AUTOSAR XML (schema 4-2-1)
package /MICROSAR/Dem_swc/DataTypes
  23 x impl type:
    Dem_EventIdType: range raw 1..65535, implementation-data-type=uint16
    Dem_RatioIdType: range raw 1..65535, implementation-data-type=uint16
    Dem_DTCStatusMaskType: range raw 0..255, implementation-data-type=uint8
    Dem_OperationCycleIdType: range raw 0..255, implementation-data-type=uint8
    Dem_DTCGroupType: range raw 0..16777215, implementation-data-type=uint32
    Dem_EventStatusType: compu {0=DEM_EVENT_STATUS_PASSED, 1=DEM_EVENT_STATUS_FAILED, 2=DEM_EVENT_STATUS_PREPASSED, 3=DEM_EVENT_STATUS_PREFAILED, 4=DEM_EVENT_STATUS_FDC_THRESHOLD_REACHED, 5=DEM_EVENT_STATUS_PASSED_CONDITIONS_NOT_FULFILLED, 6=DEM_EVENT_STATUS_FAILED_CONDITIONS_NOT_FULFILLED, 7=DEM_EVENT_STATUS_PREPASSED_CONDITIONS_NOT_FULFILLED, 8=DEM_EVENT_STATUS_PREFAILED_CONDITIONS_NOT_FULFILLED}, implementation-data-type=uint8
    Dem_InitMonitorReasonType: compu {1=DEM_INIT_MONITOR_CLEAR, 2=DEM_INIT_MONITOR_RESTART, 3=DEM_INIT_MONITOR_REENABLED, 4=DEM_INIT_MONITOR_STORAGE_REENABLED}, implementation-data-type=uint8
    Dem_DTCOriginType: compu {1=DEM_DTC_ORIGIN_PRIMARY_MEMORY, 2=DEM_DTC_ORIGIN_MIRROR_MEMORY, 3=DEM_DTC_ORIGIN_PERMANENT_MEMORY, 4=DEM_DTC_ORIGIN_OBD_RELEVANT_MEMORY, 5=DEM_DTC_ORIGIN_SECONDARY_MEMORY, 5=DEM_DTC_ORIGIN_USERDEFINED_MEMORY_10, 5=DEM_DTC_ORIGIN_USERDEFINED_MEMORY_11, 5=DEM_DTC_ORIGIN_USERDEFINED_MEMORY_12, 5=DEM_DTC_ORIGIN_USERDEFINED_MEMORY_13, 5=DEM_DTC_ORIGIN_USERDEFINED_MEMORY_14, 5=DEM_DTC_ORIGIN_USERDEFINED_MEMORY_15, 5=DEM_DTC_ORIGIN_USERDEFINED_MEMORY_16, 5=DEM_DTC_ORIGIN_USERDEFINED_MEMORY_17, 5=DEM_DTC_ORIGIN_USERDEFINED_MEMORY_18, 5=DEM_DTC_ORIGIN_USERDEFINED_MEMORY_19, 5=DEM_DTC_ORIGIN_USERDEFINED_MEMORY_1A, 5=DEM_DTC_ORIGIN_USERDEFINED_MEMORY_1B, 5=DEM_DTC_ORIGIN_USERDEFINED_MEMORY_1C, 5=DEM_DTC_ORIGIN_USERDEFINED_MEMORY_1D, 5=DEM_DTC_ORIGIN_USERDEFINED_MEMORY_1E, 5=DEM_DTC_ORIGIN_USERDEFINED_MEMORY_1F, 5=DEM_DTC_ORIGIN_USERDEFINED_MEMORY_20, 5=DEM_DTC_ORIGIN_USERDEFINED_MEMORY_21, 5=DEM_DTC_ORIGIN_USERDEFINED_MEMORY_22, 5=DEM_DTC_ORIGIN_USERDEFINED_MEMORY_23, 5=DEM_DTC_ORIGIN_USERDEFINED_MEMORY_24, 5=DEM_DTC_ORIGIN_USERDEFINED_MEMORY_25, 5=DEM_DTC_ORIGIN_USERDEFINED_MEMORY_26, 5=DEM_DTC_ORIGIN_USERDEFINED_MEMORY_27, 5=DEM_DTC_ORIGIN_USERDEFINED_MEMORY_28, 5=DEM_DTC_ORIGIN_USERDEFINED_MEMORY_29, 5=DEM_DTC_ORIGIN_USERDEFINED_MEMORY_2A, 5=DEM_DTC_ORIGIN_USERDEFINED_MEMORY_2B, 5=DEM_DTC_ORIGIN_USERDEFINED_MEMORY_2C, 5=DEM_DTC_ORIGIN_USERDEFINED_MEMORY_2D, 5=DEM_DTC_ORIGIN_USERDEFINED_MEMORY_2E, 5=DEM_DTC_ORIGIN_USERDEFINED_MEMORY_2F, 5=DEM_DTC_ORIGIN_USERDEFINED_MEMORY_30, 5=DEM_DTC_ORIGIN_USERDEFINED_MEMORY_31, 5=DEM_DTC_ORIGIN_USERDEFINED_MEMORY_32, 5=DEM_DTC_ORIGIN_USERDEFINED_MEMORY_33, 5=DEM_DTC_ORIGIN_USERDEFINED_MEMORY_34, 5=DEM_DTC_ORIGIN_USERDEFINED_MEMORY_35, 5=DEM_DTC_ORIGIN_USERDEFINED_MEMORY_36, 5=DEM_DTC_ORIGIN_USERDEFINED_MEMORY_37, 5=DEM_DTC_ORIGIN_USERDEFINED_MEMORY_38, 5=DEM_DTC_ORIGIN_USERDEFINED_MEMORY_39, 5=DEM_DTC_ORIGIN_USERDEFINED_MEMORY_3A, 5=DEM_DTC_ORIGIN_USERDEFINED_MEMORY_3B, 5=DEM_DTC_ORIGIN_USERDEFINED_MEMORY_3C, 5=DEM_DTC_ORIGIN_USERDEFINED_MEMORY_3D, 5=DEM_DTC_ORIGIN_USERDEFINED_MEMORY_3E, 5=DEM_DTC_ORIGIN_USERDEFINED_MEMORY_3F, 5=DEM_DTC_ORIGIN_USERDEFINED_MEMORY_40, 5=DEM_DTC_ORIGIN_USERDEFINED_MEMORY_41, 5=DEM_DTC_ORIGIN_USERDEFINED_MEMORY_42, 5=DEM_DTC_ORIGIN_USERDEFINED_MEMORY_43, 5=DEM_DTC_ORIGIN_USERDEFINED_MEMORY_44, 5=DEM_DTC_ORIGIN_USERDEFINED_MEMORY_45, 5=DEM_DTC_ORIGIN_USERDEFINED_MEMORY_46, 5=DEM_DTC_ORIGIN_USERDEFINED_MEMORY_47, 5=DEM_DTC_ORIGIN_USERDEFINED_MEMORY_48, 5=DEM_DTC_ORIGIN_USERDEFINED_MEMORY_49, 5=DEM_DTC_ORIGIN_USERDEFINED_MEMORY_4A, 5=DEM_DTC_ORIGIN_USERDEFINED_MEMORY_4B, 5=DEM_DTC_ORIGIN_USERDEFINED_MEMORY_4C, 5=DEM_DTC_ORIGIN_USERDEFINED_MEMORY_4D, 5=DEM_DTC_ORIGIN_USERDEFINED_MEMORY_4E, 5=DEM_DTC_ORIGIN_USERDEFINED_MEMORY_4F, 5=DEM_DTC_ORIGIN_USERDEFINED_MEMORY_50, 5=DEM_DTC_ORIGIN_USERDEFINED_MEMORY_51, 5=DEM_DTC_ORIGIN_USERDEFINED_MEMORY_52, 5=DEM_DTC_ORIGIN_USERDEFINED_MEMORY_53, 5=DEM_DTC_ORIGIN_USERDEFINED_MEMORY_54, 5=DEM_DTC_ORIGIN_USERDEFINED_MEMORY_55, 5=DEM_DTC_ORIGIN_USERDEFINED_MEMORY_56, 5=DEM_DTC_ORIGIN_USERDEFINED_MEMORY_57, 5=DEM_DTC_ORIGIN_USERDEFINED_MEMORY_58, 5=DEM_DTC_ORIGIN_USERDEFINED_MEMORY_59, 5=DEM_DTC_ORIGIN_USERDEFINED_MEMORY_5A, 5=DEM_DTC_ORIGIN_USERDEFINED_MEMORY_5B, 5=DEM_DTC_ORIGIN_USERDEFINED_MEMORY_5C, 5=DEM_DTC_ORIGIN_USERDEFINED_MEMORY_5D, 5=DEM_DTC_ORIGIN_USERDEFINED_MEMORY_5E, 5=DEM_DTC_ORIGIN_USERDEFINED_MEMORY_5F, 5=DEM_DTC_ORIGIN_USERDEFINED_MEMORY_60, 5=DEM_DTC_ORIGIN_USERDEFINED_MEMORY_61, 5=DEM_DTC_ORIGIN_USERDEFINED_MEMORY_62, 5=DEM_DTC_ORIGIN_USERDEFINED_MEMORY_63, 5=DEM_DTC_ORIGIN_USERDEFINED_MEMORY_64, 5=DEM_DTC_ORIGIN_USERDEFINED_MEMORY_65, 5=DEM_DTC_ORIGIN_USERDEFINED_MEMORY_66, 5=DEM_DTC_ORIGIN_USERDEFINED_MEMORY_67, 5=DEM_DTC_ORIGIN_USERDEFINED_MEMORY_68, 5=DEM_DTC_ORIGIN_USERDEFINED_MEMORY_69, 5=DEM_DTC_ORIGIN_USERDEFINED_MEMORY_6A, 5=DEM_DTC_ORIGIN_USERDEFINED_MEMORY_6B, 5=DEM_DTC_ORIGIN_USERDEFINED_MEMORY_6C, 5=DEM_DTC_ORIGIN_USERDEFINED_MEMORY_6D, 5=DEM_DTC_ORIGIN_USERDEFINED_MEMORY_6E, 5=DEM_DTC_ORIGIN_USERDEFINED_MEMORY_6F, 5=DEM_DTC_ORIGIN_USERDEFINED_MEMORY_70, 5=DEM_DTC_ORIGIN_USERDEFINED_MEMORY_71, 5=DEM_DTC_ORIGIN_USERDEFINED_MEMORY_72, 5=DEM_DTC_ORIGIN_USERDEFINED_MEMORY_73, 5=DEM_DTC_ORIGIN_USERDEFINED_MEMORY_74, 5=DEM_DTC_ORIGIN_USERDEFINED_MEMORY_75, 5=DEM_DTC_ORIGIN_USERDEFINED_MEMORY_76, 5=DEM_DTC_ORIGIN_USERDEFINED_MEMORY_77, 5=DEM_DTC_ORIGIN_USERDEFINED_MEMORY_78, 5=DEM_DTC_ORIGIN_USERDEFINED_MEMORY_79, 5=DEM_DTC_ORIGIN_USERDEFINED_MEMORY_7A, 5=DEM_DTC_ORIGIN_USERDEFINED_MEMORY_7B, 5=DEM_DTC_ORIGIN_USERDEFINED_MEMORY_7C, 5=DEM_DTC_ORIGIN_USERDEFINED_MEMORY_7D, 5=DEM_DTC_ORIGIN_USERDEFINED_MEMORY_7E, 5=DEM_DTC_ORIGIN_USERDEFINED_MEMORY_7F, 5=DEM_DTC_ORIGIN_USERDEFINED_MEMORY_80, 5=DEM_DTC_ORIGIN_USERDEFINED_MEMORY_81, 5=DEM_DTC_ORIGIN_USERDEFINED_MEMORY_82, 5=DEM_DTC_ORIGIN_USERDEFINED_MEMORY_83, 5=DEM_DTC_ORIGIN_USERDEFINED_MEMORY_84, 5=DEM_DTC_ORIGIN_USERDEFINED_MEMORY_85, 5=DEM_DTC_ORIGIN_USERDEFINED_MEMORY_86, 5=DEM_DTC_ORIGIN_USERDEFINED_MEMORY_87, 5=DEM_DTC_ORIGIN_USERDEFINED_MEMORY_88, 5=DEM_DTC_ORIGIN_USERDEFINED_MEMORY_89, 5=DEM_DTC_ORIGIN_USERDEFINED_MEMORY_8A, 5=DEM_DTC_ORIGIN_USERDEFINED_MEMORY_8B, 5=DEM_DTC_ORIGIN_USERDEFINED_MEMORY_8C, 5=DEM_DTC_ORIGIN_USERDEFINED_MEMORY_8D, 5=DEM_DTC_ORIGIN_USERDEFINED_MEMORY_8E, 5=DEM_DTC_ORIGIN_USERDEFINED_MEMORY_8F, 5=DEM_DTC_ORIGIN_USERDEFINED_MEMORY_90, 5=DEM_DTC_ORIGIN_USERDEFINED_MEMORY_91, 5=DEM_DTC_ORIGIN_USERDEFINED_MEMORY_92, 5=DEM_DTC_ORIGIN_USERDEFINED_MEMORY_93, 5=DEM_DTC_ORIGIN_USERDEFINED_MEMORY_94, 5=DEM_DTC_ORIGIN_USERDEFINED_MEMORY_95, 5=DEM_DTC_ORIGIN_USERDEFINED_MEMORY_96, 5=DEM_DTC_ORIGIN_USERDEFINED_MEMORY_97, 5=DEM_DTC_ORIGIN_USERDEFINED_MEMORY_98, 5=DEM_DTC_ORIGIN_USERDEFINED_MEMORY_99, 5=DEM_DTC_ORIGIN_USERDEFINED_MEMORY_9A, 5=DEM_DTC_ORIGIN_USERDEFINED_MEMORY_9B, 5=DEM_DTC_ORIGIN_USERDEFINED_MEMORY_9C, 5=DEM_DTC_ORIGIN_USERDEFINED_MEMORY_9D, 5=DEM_DTC_ORIGIN_USERDEFINED_MEMORY_9E, 5=DEM_DTC_ORIGIN_USERDEFINED_MEMORY_9F, 5=DEM_DTC_ORIGIN_USERDEFINED_MEMORY_A0, 5=DEM_DTC_ORIGIN_USERDEFINED_MEMORY_A1, 5=DEM_DTC_ORIGIN_USERDEFINED_MEMORY_A2, 5=DEM_DTC_ORIGIN_USERDEFINED_MEMORY_A3, 5=DEM_DTC_ORIGIN_USERDEFINED_MEMORY_A4, 5=DEM_DTC_ORIGIN_USERDEFINED_MEMORY_A5, 5=DEM_DTC_ORIGIN_USERDEFINED_MEMORY_A6, 5=DEM_DTC_ORIGIN_USERDEFINED_MEMORY_A7, 5=DEM_DTC_ORIGIN_USERDEFINED_MEMORY_A8, 5=DEM_DTC_ORIGIN_USERDEFINED_MEMORY_A9, 5=DEM_DTC_ORIGIN_USERDEFINED_MEMORY_AA, 5=DEM_DTC_ORIGIN_USERDEFINED_MEMORY_AB, 5=DEM_DTC_ORIGIN_USERDEFINED_MEMORY_AC, 5=DEM_DTC_ORIGIN_USERDEFINED_MEMORY_AD, 5=DEM_DTC_ORIGIN_USERDEFINED_MEMORY_AE, 5=DEM_DTC_ORIGIN_USERDEFINED_MEMORY_AF, 5=DEM_DTC_ORIGIN_USERDEFINED_MEMORY_B0, 5=DEM_DTC_ORIGIN_USERDEFINED_MEMORY_B1, 5=DEM_DTC_ORIGIN_USERDEFINED_MEMORY_B2, 5=DEM_DTC_ORIGIN_USERDEFINED_MEMORY_B3, 5=DEM_DTC_ORIGIN_USERDEFINED_MEMORY_B4, 5=DEM_DTC_ORIGIN_USERDEFINED_MEMORY_B5, 5=DEM_DTC_ORIGIN_USERDEFINED_MEMORY_B6, 5=DEM_DTC_ORIGIN_USERDEFINED_MEMORY_B7, 5=DEM_DTC_ORIGIN_USERDEFINED_MEMORY_B8, 5=DEM_DTC_ORIGIN_USERDEFINED_MEMORY_B9, 5=DEM_DTC_ORIGIN_USERDEFINED_MEMORY_BA, 5=DEM_DTC_ORIGIN_USERDEFINED_MEMORY_BB, 5=DEM_DTC_ORIGIN_USERDEFINED_MEMORY_BC, 5=DEM_DTC_ORIGIN_USERDEFINED_MEMORY_BD, 5=DEM_DTC_ORIGIN_USERDEFINED_MEMORY_BE, 5=DEM_DTC_ORIGIN_USERDEFINED_MEMORY_BF, 5=DEM_DTC_ORIGIN_USERDEFINED_MEMORY_C0, 5=DEM_DTC_ORIGIN_USERDEFINED_MEMORY_C1, 5=DEM_DTC_ORIGIN_USERDEFINED_MEMORY_C2, 5=DEM_DTC_ORIGIN_USERDEFINED_MEMORY_C3, 5=DEM_DTC_ORIGIN_USERDEFINED_MEMORY_C4, 5=DEM_DTC_ORIGIN_USERDEFINED_MEMORY_C5, 5=DEM_DTC_ORIGIN_USERDEFINED_MEMORY_C6, 5=DEM_DTC_ORIGIN_USERDEFINED_MEMORY_C7, 5=DEM_DTC_ORIGIN_USERDEFINED_MEMORY_C8, 5=DEM_DTC_ORIGIN_USERDEFINED_MEMORY_C9, 5=DEM_DTC_ORIGIN_USERDEFINED_MEMORY_CA, 5=DEM_DTC_ORIGIN_USERDEFINED_MEMORY_CB, 5=DEM_DTC_ORIGIN_USERDEFINED_MEMORY_CC, 5=DEM_DTC_ORIGIN_USERDEFINED_MEMORY_CD, 5=DEM_DTC_ORIGIN_USERDEFINED_MEMORY_CE, 5=DEM_DTC_ORIGIN_USERDEFINED_MEMORY_CF, 5=DEM_DTC_ORIGIN_USERDEFINED_MEMORY_D0, 5=DEM_DTC_ORIGIN_USERDEFINED_MEMORY_D1, 5=DEM_DTC_ORIGIN_USERDEFINED_MEMORY_D2, 5=DEM_DTC_ORIGIN_USERDEFINED_MEMORY_D3, 5=DEM_DTC_ORIGIN_USERDEFINED_MEMORY_D4, 5=DEM_DTC_ORIGIN_USERDEFINED_MEMORY_D5, 5=DEM_DTC_ORIGIN_USERDEFINED_MEMORY_D6, 5=DEM_DTC_ORIGIN_USERDEFINED_MEMORY_D7, 5=DEM_DTC_ORIGIN_USERDEFINED_MEMORY_D8, 5=DEM_DTC_ORIGIN_USERDEFINED_MEMORY_D9, 5=DEM_DTC_ORIGIN_USERDEFINED_MEMORY_DA, 5=DEM_DTC_ORIGIN_USERDEFINED_MEMORY_DB, 5=DEM_DTC_ORIGIN_USERDEFINED_MEMORY_DC, 5=DEM_DTC_ORIGIN_USERDEFINED_MEMORY_DD, 5=DEM_DTC_ORIGIN_USERDEFINED_MEMORY_DE, 5=DEM_DTC_ORIGIN_USERDEFINED_MEMORY_DF, 5=DEM_DTC_ORIGIN_USERDEFINED_MEMORY_E0, 5=DEM_DTC_ORIGIN_USERDEFINED_MEMORY_E1, 5=DEM_DTC_ORIGIN_USERDEFINED_MEMORY_E2, 5=DEM_DTC_ORIGIN_USERDEFINED_MEMORY_E3, 5=DEM_DTC_ORIGIN_USERDEFINED_MEMORY_E4, 5=DEM_DTC_ORIGIN_USERDEFINED_MEMORY_E5, 5=DEM_DTC_ORIGIN_USERDEFINED_MEMORY_E6, 5=DEM_DTC_ORIGIN_USERDEFINED_MEMORY_E7, 5=DEM_DTC_ORIGIN_USERDEFINED_MEMORY_E8, 5=DEM_DTC_ORIGIN_USERDEFINED_MEMORY_E9, 5=DEM_DTC_ORIGIN_USERDEFINED_MEMORY_EA, 5=DEM_DTC_ORIGIN_USERDEFINED_MEMORY_EB, 5=DEM_DTC_ORIGIN_USERDEFINED_MEMORY_EC, 5=DEM_DTC_ORIGIN_USERDEFINED_MEMORY_ED, 5=DEM_DTC_ORIGIN_USERDEFINED_MEMORY_EE, 5=DEM_DTC_ORIGIN_USERDEFINED_MEMORY_EF, 5=DEM_DTC_ORIGIN_USERDEFINED_MEMORY_F0, 5=DEM_DTC_ORIGIN_USERDEFINED_MEMORY_F1, 5=DEM_DTC_ORIGIN_USERDEFINED_MEMORY_F2, 5=DEM_DTC_ORIGIN_USERDEFINED_MEMORY_F3, 5=DEM_DTC_ORIGIN_USERDEFINED_MEMORY_F4, 5=DEM_DTC_ORIGIN_USERDEFINED_MEMORY_F5, 5=DEM_DTC_ORIGIN_USERDEFINED_MEMORY_F6, 5=DEM_DTC_ORIGIN_USERDEFINED_MEMORY_F7, 5=DEM_DTC_ORIGIN_USERDEFINED_MEMORY_F8, 5=DEM_DTC_ORIGIN_USERDEFINED_MEMORY_F9, 5=DEM_DTC_ORIGIN_USERDEFINED_MEMORY_FA, 5=DEM_DTC_ORIGIN_USERDEFINED_MEMORY_FB, 5=DEM_DTC_ORIGIN_USERDEFINED_MEMORY_FC, 5=DEM_DTC_ORIGIN_USERDEFINED_MEMORY_FD, 5=DEM_DTC_ORIGIN_USERDEFINED_MEMORY_FE, 5=DEM_DTC_ORIGIN_USERDEFINED_MEMORY_FF}, implementation-data-type=uint16
    Dem_DTCFormatType: compu {0=DEM_DTC_FORMAT_OBD, 1=DEM_DTC_FORMAT_UDS, 2=DEM_DTC_FORMAT_J1939}, implementation-data-type=uint8
    Dem_OperationCycleStateType: compu {0=DEM_CYCLE_STATE_START, 1=DEM_CYCLE_STATE_END}, implementation-data-type=uint8
    Dem_IndicatorStatusType: compu {0=DEM_INDICATOR_OFF, 1=DEM_INDICATOR_CONTINUOUS, 2=DEM_INDICATOR_BLINKING, 3=DEM_INDICATOR_BLINK_CONT, 4=DEM_INDICATOR_SLOW_FLASH, 5=DEM_INDICATOR_FAST_FLASH, 6=DEM_INDICATOR_ON_DEMAND, 7=DEM_INDICATOR_SHORT}, implementation-data-type=uint8
    Dem_DTCKindType: compu {1=DEM_DTC_KIND_ALL_DTCS, 2=DEM_DTC_KIND_EMISSION_REL_DTCS}, implementation-data-type=uint8
    Dem_IumprDenomCondIdType: compu {1=DEM_IUMPR_GENERAL_DENOMINATOR, 2=DEM_IUMPR_DEN_COND_COLDSTART, 3=DEM_IUMPR_DEN_COND_EVAP, 4=DEM_IUMPR_DEN_COND_500MI}, implementation-data-type=uint8
    Dem_IumprDenomCondStatusType: compu {0=DEM_IUMPR_DEN_STATUS_NOT_REACHED, 1=DEM_IUMPR_DEN_STATUS_REACHED, 2=DEM_IUMPR_DEN_STATUS_INHIBITED}, implementation-data-type=uint8
    Dem_DebounceResetStatusType: compu {0=DEM_DEBOUNCE_STATUS_FREEZE, 1=DEM_DEBOUNCE_STATUS_RESET}, implementation-data-type=uint8
    Dem_IumprReadinessGroupType: compu {0=DEM_IUMPR_BOOSTPRS, 1=DEM_IUMPR_CAT1, 2=DEM_IUMPR_CAT2, 3=DEM_IUMPR_EGR, 4=DEM_IUMPR_EGSENSOR, 5=DEM_IUMPR_EVAP, 6=DEM_IUMPR_NMHCCAT, 7=DEM_IUMPR_NOXADSORB, 8=DEM_IUMPR_NOXCAT, 9=DEM_IUMPR_OXS1, 10=DEM_IUMPR_OXS2, 11=DEM_IUMPR_PMFILTER, 12=DEM_IUMPR_PRIVATE, 13=DEM_IUMPR_SAIR, 14=DEM_IUMPR_SECOXS1, 15=DEM_IUMPR_SECOXS2, 16=DEM_IUMPR_FLSYS, 255=DEM_IUMPR_ALLGROUPS}, implementation-data-type=uint8
    Dem_DTRControlType: compu {0=DEM_DTR_CTL_NORMAL, 1=DEM_DTR_CTL_NO_MAX, 2=DEM_DTR_CTL_NO_MIN, 3=DEM_DTR_CTL_RESET, 4=DEM_DTR_CTL_INVISIBLE}, implementation-data-type=uint8
    Dem_DebouncingStateType: compu {mask 1: 1=DEM_TEMPORARILY_DEFECTIVE, mask 2: 2=DEM_FINALLY_DEFECTIVE, mask 4: 4=DEM_TEMPORARILY_HEALED, mask 8: 8=DEM_TEST_COMPLETE, mask 16: 16=DEM_DTR_UPDATE}, range raw 0..255, implementation-data-type=uint8
    Dem_DTCSeverityType:
      compu {mask 255: 0=DEM_SEVERITY_NO_SEVERITY, mask 31: 2=DEM_SEVERITY_WWHOBD_CLASS_A, mask 31: 4=DEM_SEVERITY_WWHOBD_CLASS_B1, mask 31: 8=DEM_SEVERITY_WWHOBD_CLASS_B2, mask 31: 16=DEM_SEVERITY_WWHOBD_CLASS_C, mask 31: 1=DEM_SEVERITY_WWHOBD_CLASS_NO_CLASS, mask 224: 64=DEM_SEVERITY_CHECK_AT_NEXT_HALT, mask 224: 128=DEM_SEVERITY_CHECK_IMMEDIATELY, mask 224: 32=DEM_SEVERITY_MAINTENANCE_ONLY}
      range raw 0..255
      implementation-data-type=uint8
    Dem_UdsStatusByteType: compu {mask 1: 1=DEM_UDS_STATUS_TF, mask 2: 2=DEM_UDS_STATUS_TFTOC, mask 4: 4=DEM_UDS_STATUS_PDTC, mask 8: 8=DEM_UDS_STATUS_CDTC, mask 16: 16=DEM_UDS_STATUS_TNCSLC, mask 32: 32=DEM_UDS_STATUS_TFSLC, mask 64: 64=DEM_UDS_STATUS_TNCTOC, mask 128: 128=DEM_UDS_STATUS_WIR}, range raw 0..255, implementation-data-type=uint8
    Dem_MonitorStatusType: compu {mask 1: 1=DEM_MONITOR_STATUS_TF, mask 2: 2=DEM_MONITOR_STATUS_TNCTOC}, range raw 0..255, implementation-data-type=uint8
    Dem_MaxDataValueType: category=ARRAY, sw-calibration-access=READ-ONLY
      element Dem_MaxDataValueTypeElement: array-size=4, array-size-semantics=FIXED-SIZE, implementation-data-type=uint8
    DataArrayType_uint8_4: category=ARRAY, sw-calibration-access=READ-ONLY
      element DataArrayType_uint8_4Element: array-size=4, array-size-semantics=FIXED-SIZE, implementation-data-type=uint8
package /MICROSAR/Dem_swc/Interfaces
  9 x client server interface, all with is-service=true, service-kind=DIAGNOSTIC-EVENT-MANAGER:
    DemServices
      operation GetPostRunRequested: possible-error=DemServices/E_NOT_OK
        arg IsRequested: type=boolean, direction=OUT
      operation GetDTCStatusAvailabilityMask: possible-error=DemServices/E_NOT_OK
        arg ClientId: type=uint8, direction=IN
        arg DTCStatusMask: type=uint8, direction=OUT
      error E_NOT_OK: error-code=1
    ClearDTC
      operation ClearDTC: possible-error=[ClearDTC/E_NOT_OK, DEM_CLEAR_FAILED, DEM_PENDING, DEM_CLEAR_BUSY, DEM_CLEAR_MEMORY_ERROR, DEM_WRONG_DTC, DEM_WRONG_DTCORIGIN]
      operation SelectDTC: possible-error=[ClearDTC/E_OK, ClearDTC/E_NOT_OK]
        arg DTC: type=uint32, direction=IN
        arg DTCFormat: type=Dem_DTCFormatType, direction=IN
        arg DTCOrigin: type=Dem_DTCOriginType, direction=IN
      8 x error:
        E_OK: error-code=0
        E_NOT_OK: error-code=1
        DEM_CLEAR_FAILED: error-code=7
        DEM_PENDING: error-code=4
        DEM_CLEAR_BUSY: error-code=5
        DEM_CLEAR_MEMORY_ERROR: error-code=6
        DEM_WRONG_DTC: error-code=8
        DEM_WRONG_DTCORIGIN: error-code=9
    EvMemOverflowIndication
      operation GetEventMemoryOverflow: possible-error=EvMemOverflowIndication/E_NOT_OK
        arg OverflowIndication: type=boolean, direction=OUT
      operation GetNumberOfEventMemoryEntries: possible-error=EvMemOverflowIndication/E_NOT_OK
        arg NumberOfEventMemoryEntries: type=uint8, direction=OUT
      error E_NOT_OK: error-code=1
    OperationCycle
      operation GetOperationCycleState: possible-error=[OperationCycle/E_OK, OperationCycle/E_NOT_OK]
        arg CycleState: type=Dem_OperationCycleStateType, direction=OUT
      operation SetOperationCycleState: possible-error=[OperationCycle/E_OK, OperationCycle/E_NOT_OK]
        arg CycleState: type=Dem_OperationCycleStateType, direction=IN
      error E_OK: error-code=0
      error E_NOT_OK: error-code=1
    GeneralDiagnosticInfo
      11 x operation:
        GetEventUdsStatus: possible-error=GeneralDiagnosticInfo/E_NOT_OK
          arg EventId: type=Dem_EventIdType, direction=IN
          arg UDSStatusByte: type=Dem_UdsStatusByteType, direction=OUT
        GetEventStatus: possible-error=GeneralDiagnosticInfo/E_NOT_OK
          arg EventId: type=Dem_EventIdType, direction=IN
          arg UDSStatusByte: type=Dem_UdsStatusByteType, direction=OUT
        GetEventFailed: possible-error=GeneralDiagnosticInfo/E_NOT_OK
          arg EventId: type=Dem_EventIdType, direction=IN
          arg EventFailed: type=boolean, direction=OUT
        GetEventTested: possible-error=GeneralDiagnosticInfo/E_NOT_OK
          arg EventId: type=Dem_EventIdType, direction=IN
          arg EventTested: type=boolean, direction=OUT
        GetDTCOfEvent: possible-error=[GeneralDiagnosticInfo/E_NOT_OK, GeneralDiagnosticInfo/DEM_E_NO_DTC_AVAILABLE]
          arg EventId: type=Dem_EventIdType, direction=IN
          arg DTCFormat: type=Dem_DTCFormatType, direction=IN
          arg DTCOfEvent: type=uint32, direction=OUT
        GetFaultDetectionCounter: possible-error=[GeneralDiagnosticInfo/E_NOT_OK, GeneralDiagnosticInfo/DEM_E_NO_FDC_AVAILABLE]
          arg EventId: type=Dem_EventIdType, direction=IN
          arg FaultDetectionCounter: type=sint8, direction=OUT
        GetEventFreezeFrameDataEx: possible-error=[GeneralDiagnosticInfo/E_NOT_OK, GeneralDiagnosticInfo/DEM_BUFFER_TOO_SMALL, GeneralDiagnosticInfo/DEM_NO_SUCH_ELEMENT]
          5 x arg:
            EventId: type=Dem_EventIdType, direction=IN
            RecordNumber: type=uint8, direction=IN
            DataId: type=uint16, direction=IN
            DestBuffer: type=Dem_MaxDataValueType, direction=OUT
            BufSize: type=uint16, direction=INOUT
        GetEventExtendedDataRecordEx: possible-error=[GeneralDiagnosticInfo/E_NOT_OK, GeneralDiagnosticInfo/DEM_BUFFER_TOO_SMALL, GeneralDiagnosticInfo/DEM_NO_SUCH_ELEMENT]
          4 x arg:
            EventId: type=Dem_EventIdType, direction=IN
            RecordNumber: type=uint8, direction=IN
            DestBuffer: type=Dem_MaxDataValueType, direction=OUT
            BufSize: type=uint16, direction=INOUT
        GetEventEnableCondition: possible-error=GeneralDiagnosticInfo/E_NOT_OK
          arg EventId: type=Dem_EventIdType, direction=IN
          arg ConditionFullfilled: type=boolean, direction=OUT
        GetDebouncingOfEvent: possible-error=GeneralDiagnosticInfo/E_NOT_OK
          arg EventId: type=Dem_EventIdType, direction=IN
          arg DebouncingState: type=Dem_DebouncingStateType, direction=OUT
        GetMonitorStatus: possible-error=GeneralDiagnosticInfo/E_NOT_OK
          arg EventId: type=Dem_EventIdType, direction=IN
          arg MonitorStatus: type=Dem_MonitorStatusType, direction=OUT
      5 x error:
        E_NOT_OK: error-code=1
        DEM_E_NO_DTC_AVAILABLE: error-code=10
        DEM_E_NO_FDC_AVAILABLE: error-code=14
        DEM_BUFFER_TOO_SMALL: error-code=21
        DEM_NO_SUCH_ELEMENT: error-code=48
    DiagnosticInfo
      11 x operation:
        GetEventUdsStatus: possible-error=DiagnosticInfo/E_NOT_OK
          arg UDSStatusByte: type=Dem_UdsStatusByteType, direction=OUT
        GetEventStatus: possible-error=DiagnosticInfo/E_NOT_OK
          arg UDSStatusByte: type=Dem_UdsStatusByteType, direction=OUT
        GetEventFailed: possible-error=DiagnosticInfo/E_NOT_OK
          arg EventFailed: type=boolean, direction=OUT
        GetEventTested: possible-error=DiagnosticInfo/E_NOT_OK
          arg EventTested: type=boolean, direction=OUT
        GetDTCOfEvent: possible-error=[DiagnosticInfo/E_NOT_OK, DiagnosticInfo/DEM_E_NO_DTC_AVAILABLE]
          arg DTCFormat: type=Dem_DTCFormatType, direction=IN
          arg DTCOfEvent: type=uint32, direction=OUT
        GetFaultDetectionCounter: possible-error=[DiagnosticInfo/E_NOT_OK, DiagnosticInfo/DEM_E_NO_FDC_AVAILABLE]
          arg FaultDetectionCounter: type=sint8, direction=OUT
        GetEventFreezeFrameDataEx: possible-error=[DiagnosticInfo/E_NOT_OK, DiagnosticInfo/DEM_BUFFER_TOO_SMALL, DiagnosticInfo/DEM_NO_SUCH_ELEMENT]
          4 x arg:
            RecordNumber: type=uint8, direction=IN
            DataId: type=uint16, direction=IN
            DestBuffer: type=Dem_MaxDataValueType, direction=OUT
            BufSize: type=uint16, direction=INOUT
        GetEventExtendedDataRecordEx: possible-error=[DiagnosticInfo/E_NOT_OK, DiagnosticInfo/DEM_BUFFER_TOO_SMALL, DiagnosticInfo/DEM_NO_SUCH_ELEMENT]
          arg RecordNumber: type=uint8, direction=IN
          arg DestBuffer: type=Dem_MaxDataValueType, direction=OUT
          arg BufSize: type=uint16, direction=INOUT
        GetEventEnableCondition: possible-error=DiagnosticInfo/E_NOT_OK
          arg ConditionFullfilled: type=boolean, direction=OUT
        GetDebouncingOfEvent: possible-error=DiagnosticInfo/E_NOT_OK
          arg DebouncingState: type=Dem_DebouncingStateType, direction=OUT
        GetMonitorStatus: possible-error=DiagnosticInfo/E_NOT_OK
          arg MonitorStatus: type=Dem_MonitorStatusType, direction=OUT
      5 x error:
        E_NOT_OK: error-code=1
        DEM_E_NO_DTC_AVAILABLE: error-code=10
        DEM_E_NO_FDC_AVAILABLE: error-code=14
        DEM_BUFFER_TOO_SMALL: error-code=21
        DEM_NO_SUCH_ELEMENT: error-code=48
    CSDataServices_OccurrenceCounter_OccurenceCounter
      operation ReadData: possible-error=CSDataServices_OccurrenceCounter_OccurenceCounter/E_NOT_OK
        arg Data: type=DataArrayType_uint8_4, direction=OUT
      error E_NOT_OK: error-code=1
    CSDataServices_OdometerValue_OdometerValue
      operation ReadData: possible-error=CSDataServices_OdometerValue_OdometerValue/E_NOT_OK
        arg Data: type=DataArrayType_uint8_4, direction=OUT
      error E_NOT_OK: error-code=1
    DiagnosticMonitor
      11 x operation:
        SetEventStatus: possible-error=DiagnosticMonitor/E_NOT_OK
          arg EventStatus: type=Dem_EventStatusType, direction=IN
        ResetEventStatus: possible-error=DiagnosticMonitor/E_NOT_OK
        ResetEventDebounceStatus: possible-error=DiagnosticMonitor/E_NOT_OK
          arg DebounceResetStatus: type=Dem_DebounceResetStatusType, direction=IN
        GetEventUdsStatus: possible-error=DiagnosticMonitor/E_NOT_OK
          arg UDSStatusByte: type=Dem_UdsStatusByteType, direction=OUT
        GetEventStatus: possible-error=DiagnosticMonitor/E_NOT_OK
          arg UDSStatusByte: type=Dem_UdsStatusByteType, direction=OUT
        GetEventFailed: possible-error=DiagnosticMonitor/E_NOT_OK
          arg EventFailed: type=boolean, direction=OUT
        GetEventTested: possible-error=DiagnosticMonitor/E_NOT_OK
          arg EventTested: type=boolean, direction=OUT
        GetDTCOfEvent: possible-error=[DiagnosticMonitor/E_NOT_OK, DiagnosticMonitor/DEM_E_NO_DTC_AVAILABLE]
          arg DTCFormat: type=Dem_DTCFormatType, direction=IN
          arg DTCOfEvent: type=uint32, direction=OUT
        GetFaultDetectionCounter: possible-error=[DiagnosticMonitor/E_NOT_OK, DiagnosticMonitor/DEM_E_NO_FDC_AVAILABLE]
          arg FaultDetectionCounter: type=sint8, direction=OUT
        GetEventFreezeFrameDataEx: possible-error=[DiagnosticMonitor/E_NOT_OK, DiagnosticMonitor/DEM_BUFFER_TOO_SMALL, DiagnosticMonitor/DEM_NO_SUCH_ELEMENT]
          4 x arg:
            RecordNumber: type=uint8, direction=IN
            DataId: type=uint16, direction=IN
            DestBuffer: type=Dem_MaxDataValueType, direction=OUT
            BufSize: type=uint16, direction=INOUT
        GetEventExtendedDataRecordEx: possible-error=[DiagnosticMonitor/E_NOT_OK, DiagnosticMonitor/DEM_BUFFER_TOO_SMALL, DiagnosticMonitor/DEM_NO_SUCH_ELEMENT]
          arg RecordNumber: type=uint8, direction=IN
          arg DestBuffer: type=Dem_MaxDataValueType, direction=OUT
          arg BufSize: type=uint16, direction=INOUT
      5 x error:
        E_NOT_OK: error-code=1
        DEM_E_NO_DTC_AVAILABLE: error-code=10
        DEM_E_NO_FDC_AVAILABLE: error-code=14
        DEM_BUFFER_TOO_SMALL: error-code=21
        DEM_NO_SUCH_ELEMENT: error-code=48
package /MICROSAR/Dem_swc/ComponentTypes
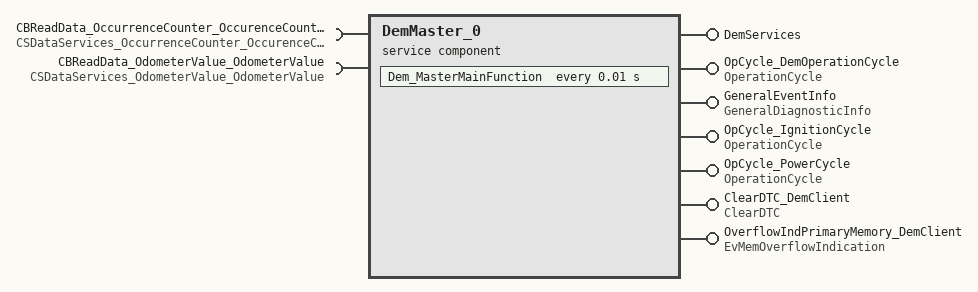
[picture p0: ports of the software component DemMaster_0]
  service sw component type DemMaster_0: category=SERVICE_COMPONENT
    5 x provide port:
      DemServices: provided-interface=DemServices
      OpCycle_DemOperationCycle: provided-interface=OperationCycle
      GeneralEventInfo: provided-interface=GeneralDiagnosticInfo
      OpCycle_IgnitionCycle: provided-interface=OperationCycle
      OpCycle_PowerCycle: provided-interface=OperationCycle
    require port CBReadData_OccurrenceCounter_OccurenceCounter: required-interface=CSDataServices_OccurrenceCounter_OccurenceCounter
    require port CBReadData_OdometerValue_OdometerValue: required-interface=CSDataServices_OdometerValue_OdometerValue
    provide port ClearDTC_DemClient: provided-interface=ClearDTC
    provide port OverflowIndPrimaryMemory_DemClient: provided-interface=EvMemOverflowIndication
    behavior DemMaster_0InternalBehavior: handle-termination-and-restart=NO-SUPPORT, included-data-type-set=data-type=[Dem_EventIdType, Dem_RatioIdType, Dem_EventStatusType, Dem_UdsStatusByteType, Dem_DTCFormatType, Dem_InitMonitorReasonType, Dem_OperationCycleStateType, Dem_DTCStatusMaskType, Dem_IndicatorStatusType, Dem_MaxDataValueType, Dem_DTCKindType, Dem_DTCGroupType, Dem_IumprDenomCondIdType, Dem_IumprDenomCondStatusType, Dem_DebounceResetStatusType, Dem_DebouncingStateType, Dem_IumprReadinessGroupType, Dem_DTRControlType, Dem_DTCSeverityType, Dem_MonitorStatusType]
      timing event Timer_Dem_MasterMainFunction: start-on-event=Dem_MasterMainFunction, period=0.01
      23 x operation invoked event:
        OpEventPostRunRequested_GetPostRunRequested_DemServices: start-on-event=PostRunRequested, operation=DemServices.GetPostRunRequested
        OpEventGetDTCStatusAvailabilityMask_GetDTCStatusAvailabilityMask_DemServices: start-on-event=GetDTCStatusAvailabilityMask, operation=DemServices.GetDTCStatusAvailabilityMask
        OpEventGetOperationCycleState_GetOperationCycleState_OpCycle_DemOperationCycle: start-on-event=GetOperationCycleState, operation=OpCycle_DemOperationCycle.GetOperationCycleState
        OpEventSetOperationCycleState_SetOperationCycleState_OpCycle_DemOperationCycle: start-on-event=SetOperationCycleState, operation=OpCycle_DemOperationCycle.SetOperationCycleState
        OpEventGetEventUdsStatus_GetEventUdsStatus_GeneralEventInfo: start-on-event=DemMaster_0InternalBehavior/GetEventUdsStatus, operation=GeneralEventInfo.GetEventUdsStatus
        OpEventGetEventStatus_GetEventStatus_GeneralEventInfo: start-on-event=DemMaster_0InternalBehavior/GetEventStatus, operation=GeneralEventInfo.GetEventStatus
        OpEventGetEventFailed_GetEventFailed_GeneralEventInfo: start-on-event=DemMaster_0InternalBehavior/GetEventFailed, operation=GeneralEventInfo.GetEventFailed
        OpEventGetEventTested_GetEventTested_GeneralEventInfo: start-on-event=DemMaster_0InternalBehavior/GetEventTested, operation=GeneralEventInfo.GetEventTested
        OpEventGetDTCOfEvent_GetDTCOfEvent_GeneralEventInfo: start-on-event=DemMaster_0InternalBehavior/GetDTCOfEvent, operation=GeneralEventInfo.GetDTCOfEvent
        OpEventGetFaultDetectionCounter_GetFaultDetectionCounter_GeneralEventInfo: start-on-event=DemMaster_0InternalBehavior/GetFaultDetectionCounter, operation=GeneralEventInfo.GetFaultDetectionCounter
        OpEventGetEventFreezeFrameDataEx_GetEventFreezeFrameDataEx_GeneralEventInfo: start-on-event=DemMaster_0InternalBehavior/GetEventFreezeFrameDataEx, operation=GeneralEventInfo.GetEventFreezeFrameDataEx
        OpEventGetEventExtendedDataRecordEx_GetEventExtendedDataRecordEx_GeneralEventInfo: start-on-event=DemMaster_0InternalBehavior/GetEventExtendedDataRecordEx, operation=GeneralEventInfo.GetEventExtendedDataRecordEx
        OpEventGetEventEnableCondition_GetEventEnableCondition_GeneralEventInfo: start-on-event=DemMaster_0InternalBehavior/GetEventEnableCondition, operation=GeneralEventInfo.GetEventEnableCondition
        OpEventGetDebouncingOfEvent_GetDebouncingOfEvent_GeneralEventInfo: start-on-event=DemMaster_0InternalBehavior/GetDebouncingOfEvent, operation=GeneralEventInfo.GetDebouncingOfEvent
        OpEventGetMonitorStatus_GetMonitorStatus_GeneralEventInfo: start-on-event=DemMaster_0InternalBehavior/GetMonitorStatus, operation=GeneralEventInfo.GetMonitorStatus
        OpEventGetOperationCycleState_GetOperationCycleState_OpCycle_IgnitionCycle: start-on-event=GetOperationCycleState, operation=OpCycle_IgnitionCycle.GetOperationCycleState
        OpEventGetOperationCycleState_GetOperationCycleState_OpCycle_PowerCycle: start-on-event=GetOperationCycleState, operation=OpCycle_PowerCycle.GetOperationCycleState
        OpEventSetOperationCycleState_SetOperationCycleState_OpCycle_IgnitionCycle: start-on-event=SetOperationCycleState, operation=OpCycle_IgnitionCycle.SetOperationCycleState
        OpEventSetOperationCycleState_SetOperationCycleState_OpCycle_PowerCycle: start-on-event=SetOperationCycleState, operation=OpCycle_PowerCycle.SetOperationCycleState
        OpEventClearDTC_ClearDTC_ClearDTC_DemClient: start-on-event=ClearDTC, operation=ClearDTC_DemClient.ClearDTC
        OpEventSelectDTC_SelectDTC_ClearDTC_DemClient: start-on-event=SelectDTC, operation=ClearDTC_DemClient.SelectDTC
        OpEventGetEventMemoryOverflow_GetEventMemoryOverflow_OverflowIndPrimaryMemory_DemClient: start-on-event=GetEventMemoryOverflow, operation=OverflowIndPrimaryMemory_DemClient.GetEventMemoryOverflow
        OpEventGetNumberOfEventMemoryEntries_GetNumberOfEventMemoryEntries_OverflowIndPrimaryMemory_DemClient: start-on-event=GetNumberOfEventMemoryEntries, operation=OverflowIndPrimaryMemory_DemClient.GetNumberOfEventMemoryEntries
      port-api-options:
        enable-take-address=true, indirect-api=false, port=DemServices
        {enable-take-address=true, indirect-api=false, port-defined-argument-value{value=0, value-type=Dem_OperationCycleIdType}, port=OpCycle_DemOperationCycle}
        enable-take-address=true, indirect-api=false, port=DemMaster_0/GeneralEventInfo
        {enable-take-address=true, indirect-api=false, port-defined-argument-value{value=1, value-type=Dem_OperationCycleIdType}, port=OpCycle_IgnitionCycle}
        {enable-take-address=true, indirect-api=false, port-defined-argument-value{value=2, value-type=Dem_OperationCycleIdType}, port=OpCycle_PowerCycle}
        enable-take-address=true, indirect-api=false, port=CBReadData_OccurrenceCounter_OccurenceCounter
        enable-take-address=true, indirect-api=false, port=CBReadData_OdometerValue_OdometerValue
        {enable-take-address=true, indirect-api=false, port-defined-argument-value{value=0, value-type=uint8}, port=ClearDTC_DemClient}
        {enable-take-address=true, indirect-api=false, port-arg-values=[{value=0, value-type=uint8}, {value=1, value-type=Dem_DTCOriginType}], port=OverflowIndPrimaryMemory_DemClient}
      20 x runnable:
        Dem_MasterMainFunction
          sync call OpServerCallDem_MasterMainFunction_ReadData_CBReadData_OccurrenceCounter_OccurenceCounter: operation=CBReadData_OccurrenceCounter_OccurenceCounter.ReadData, timeout=0
          sync call OpServerCallDem_MasterMainFunction_ReadData_CBReadData_OdometerValue_OdometerValue: operation=CBReadData_OdometerValue_OdometerValue.ReadData, timeout=0
        PostRunRequested: can-be-invoked-concurrently=true, symbol=Dem_PostRunRequested
        GetDTCStatusAvailabilityMask: can-be-invoked-concurrently=true, symbol=Dem_GetDTCStatusAvailabilityMask
        GetOperationCycleState: can-be-invoked-concurrently=true, symbol=Dem_GetOperationCycleState
        SetOperationCycleState: can-be-invoked-concurrently=true, symbol=Dem_SetOperationCycleState
        GetEventUdsStatus: can-be-invoked-concurrently=true, symbol=Dem_GetEventUdsStatus
        GetEventStatus: can-be-invoked-concurrently=true, symbol=Dem_GetEventUdsStatus
        GetEventFailed: can-be-invoked-concurrently=true, symbol=Dem_GetEventFailed
        GetEventTested: can-be-invoked-concurrently=true, symbol=Dem_GetEventTested
        GetDTCOfEvent: can-be-invoked-concurrently=true, symbol=Dem_GetDTCOfEvent
        GetFaultDetectionCounter: can-be-invoked-concurrently=true, symbol=Dem_GetFaultDetectionCounter
        GetEventFreezeFrameDataEx: can-be-invoked-concurrently=true, symbol=Dem_GetEventFreezeFrameDataEx
        GetEventExtendedDataRecordEx: can-be-invoked-concurrently=true, symbol=Dem_GetEventExtendedDataRecordEx
        GetEventEnableCondition: can-be-invoked-concurrently=true, symbol=Dem_GetEventEnableCondition
        GetDebouncingOfEvent: can-be-invoked-concurrently=true, symbol=Dem_GetDebouncingOfEvent
        GetMonitorStatus: can-be-invoked-concurrently=true, symbol=Dem_GetMonitorStatus
        ClearDTC: can-be-invoked-concurrently=true, symbol=Dem_ClearDTC
        SelectDTC: can-be-invoked-concurrently=true, symbol=Dem_SelectDTC
        GetEventMemoryOverflow: can-be-invoked-concurrently=true, symbol=Dem_GetEventMemoryOverflow
        GetNumberOfEventMemoryEntries: can-be-invoked-concurrently=true, symbol=Dem_GetNumberOfEventMemoryEntries
  swc implementation DemMaster_0Implementation: programming-language=C, behavior=DemMaster_0InternalBehavior
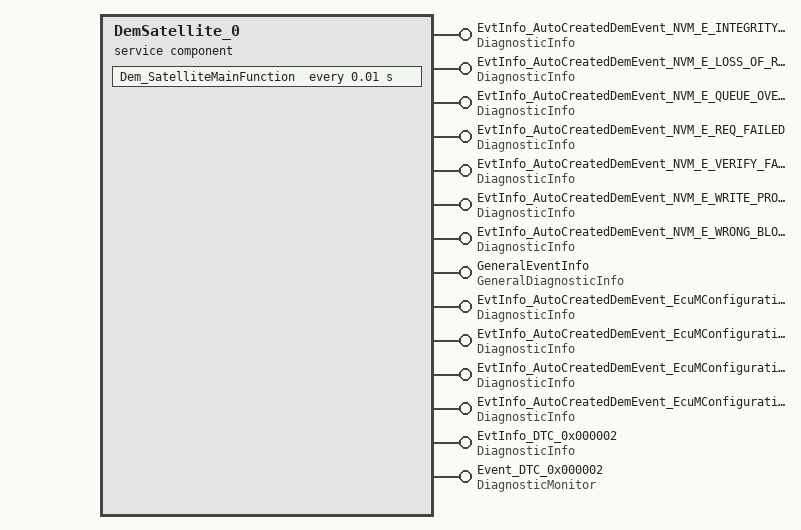
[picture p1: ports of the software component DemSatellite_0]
  service sw component type DemSatellite_0: category=SERVICE_COMPONENT
    14 x provide port:
      EvtInfo_AutoCreatedDemEvent_NVM_E_INTEGRITY_FAILED: provided-interface=DiagnosticInfo
      EvtInfo_AutoCreatedDemEvent_NVM_E_LOSS_OF_REDUNDANCY: provided-interface=DiagnosticInfo
      EvtInfo_AutoCreatedDemEvent_NVM_E_QUEUE_OVERFLOW: provided-interface=DiagnosticInfo
      EvtInfo_AutoCreatedDemEvent_NVM_E_REQ_FAILED: provided-interface=DiagnosticInfo
      EvtInfo_AutoCreatedDemEvent_NVM_E_VERIFY_FAILED: provided-interface=DiagnosticInfo
      EvtInfo_AutoCreatedDemEvent_NVM_E_WRITE_PROTECTED: provided-interface=DiagnosticInfo
      EvtInfo_AutoCreatedDemEvent_NVM_E_WRONG_BLOCK_ID: provided-interface=DiagnosticInfo
      GeneralEventInfo: provided-interface=GeneralDiagnosticInfo
      EvtInfo_AutoCreatedDemEvent_EcuMConfiguration_ECUM_E_ALL_RUN_REQUESTS_KILLED: provided-interface=DiagnosticInfo
      EvtInfo_AutoCreatedDemEvent_EcuMConfiguration_ECUM_E_CONFIGURATION_DATA_INCONSISTENT: provided-interface=DiagnosticInfo
      EvtInfo_AutoCreatedDemEvent_EcuMConfiguration_ECUM_E_RAM_CHECK_FAILED: provided-interface=DiagnosticInfo
      EvtInfo_AutoCreatedDemEvent_EcuMConfiguration_ECUM_E_IMPROPER_CALLER: provided-interface=DiagnosticInfo
      EvtInfo_DTC_0x000002: provided-interface=DiagnosticInfo
      Event_DTC_0x000002: provided-interface=DiagnosticMonitor
    behavior DemSatellite_0InternalBehavior: handle-termination-and-restart=NO-SUPPORT, included-data-type-set=data-type=[Dem_EventIdType, Dem_RatioIdType, Dem_EventStatusType, Dem_UdsStatusByteType, Dem_DTCFormatType, Dem_InitMonitorReasonType, Dem_OperationCycleStateType, Dem_DTCStatusMaskType, Dem_IndicatorStatusType, Dem_MaxDataValueType, Dem_DTCKindType, Dem_DTCGroupType, Dem_IumprDenomCondIdType, Dem_IumprDenomCondStatusType, Dem_DebounceResetStatusType, Dem_DebouncingStateType, Dem_IumprReadinessGroupType, Dem_DTRControlType, Dem_DTCSeverityType, Dem_MonitorStatusType]
      timing event Timer_Dem_SatelliteMainFunction: start-on-event=Dem_SatelliteMainFunction, period=0.01
      154 x operation invoked event:
        OpEventGetEventUdsStatus_GetEventUdsStatus_EvtInfo_AutoCreatedDemEvent_NVM_E_INTEGRITY_FAILED: start-on-event=DemSatellite_0InternalBehavior/GetEventUdsStatus, operation=EvtInfo_AutoCreatedDemEvent_NVM_E_INTEGRITY_FAILED.GetEventUdsStatus
        OpEventGetEventUdsStatus_GetEventUdsStatus_EvtInfo_AutoCreatedDemEvent_NVM_E_LOSS_OF_REDUNDANCY: start-on-event=DemSatellite_0InternalBehavior/GetEventUdsStatus, operation=EvtInfo_AutoCreatedDemEvent_NVM_E_LOSS_OF_REDUNDANCY.GetEventUdsStatus
        OpEventGetEventUdsStatus_GetEventUdsStatus_EvtInfo_AutoCreatedDemEvent_NVM_E_QUEUE_OVERFLOW: start-on-event=DemSatellite_0InternalBehavior/GetEventUdsStatus, operation=EvtInfo_AutoCreatedDemEvent_NVM_E_QUEUE_OVERFLOW.GetEventUdsStatus
        OpEventGetEventUdsStatus_GetEventUdsStatus_EvtInfo_AutoCreatedDemEvent_NVM_E_REQ_FAILED: start-on-event=DemSatellite_0InternalBehavior/GetEventUdsStatus, operation=EvtInfo_AutoCreatedDemEvent_NVM_E_REQ_FAILED.GetEventUdsStatus
        OpEventGetEventUdsStatus_GetEventUdsStatus_EvtInfo_AutoCreatedDemEvent_NVM_E_VERIFY_FAILED: start-on-event=DemSatellite_0InternalBehavior/GetEventUdsStatus, operation=EvtInfo_AutoCreatedDemEvent_NVM_E_VERIFY_FAILED.GetEventUdsStatus
        OpEventGetEventUdsStatus_GetEventUdsStatus_EvtInfo_AutoCreatedDemEvent_NVM_E_WRITE_PROTECTED: start-on-event=DemSatellite_0InternalBehavior/GetEventUdsStatus, operation=EvtInfo_AutoCreatedDemEvent_NVM_E_WRITE_PROTECTED.GetEventUdsStatus
        OpEventGetEventUdsStatus_GetEventUdsStatus_EvtInfo_AutoCreatedDemEvent_NVM_E_WRONG_BLOCK_ID: start-on-event=DemSatellite_0InternalBehavior/GetEventUdsStatus, operation=EvtInfo_AutoCreatedDemEvent_NVM_E_WRONG_BLOCK_ID.GetEventUdsStatus
        OpEventGetEventUdsStatus_GetEventUdsStatus_GeneralEventInfo: start-on-event=DemSatellite_0InternalBehavior/GetEventUdsStatus, operation=GeneralEventInfo.GetEventUdsStatus
        OpEventGetEventStatus_GetEventStatus_EvtInfo_AutoCreatedDemEvent_NVM_E_INTEGRITY_FAILED: start-on-event=DemSatellite_0InternalBehavior/GetEventStatus, operation=EvtInfo_AutoCreatedDemEvent_NVM_E_INTEGRITY_FAILED.GetEventStatus
        OpEventGetEventStatus_GetEventStatus_EvtInfo_AutoCreatedDemEvent_NVM_E_LOSS_OF_REDUNDANCY: start-on-event=DemSatellite_0InternalBehavior/GetEventStatus, operation=EvtInfo_AutoCreatedDemEvent_NVM_E_LOSS_OF_REDUNDANCY.GetEventStatus
        OpEventGetEventStatus_GetEventStatus_EvtInfo_AutoCreatedDemEvent_NVM_E_QUEUE_OVERFLOW: start-on-event=DemSatellite_0InternalBehavior/GetEventStatus, operation=EvtInfo_AutoCreatedDemEvent_NVM_E_QUEUE_OVERFLOW.GetEventStatus
        OpEventGetEventStatus_GetEventStatus_EvtInfo_AutoCreatedDemEvent_NVM_E_REQ_FAILED: start-on-event=DemSatellite_0InternalBehavior/GetEventStatus, operation=EvtInfo_AutoCreatedDemEvent_NVM_E_REQ_FAILED.GetEventStatus
        OpEventGetEventStatus_GetEventStatus_EvtInfo_AutoCreatedDemEvent_NVM_E_VERIFY_FAILED: start-on-event=DemSatellite_0InternalBehavior/GetEventStatus, operation=EvtInfo_AutoCreatedDemEvent_NVM_E_VERIFY_FAILED.GetEventStatus
        OpEventGetEventStatus_GetEventStatus_EvtInfo_AutoCreatedDemEvent_NVM_E_WRITE_PROTECTED: start-on-event=DemSatellite_0InternalBehavior/GetEventStatus, operation=EvtInfo_AutoCreatedDemEvent_NVM_E_WRITE_PROTECTED.GetEventStatus
        OpEventGetEventStatus_GetEventStatus_EvtInfo_AutoCreatedDemEvent_NVM_E_WRONG_BLOCK_ID: start-on-event=DemSatellite_0InternalBehavior/GetEventStatus, operation=EvtInfo_AutoCreatedDemEvent_NVM_E_WRONG_BLOCK_ID.GetEventStatus
        OpEventGetEventStatus_GetEventStatus_GeneralEventInfo: start-on-event=DemSatellite_0InternalBehavior/GetEventStatus, operation=GeneralEventInfo.GetEventStatus
        OpEventGetEventFailed_GetEventFailed_EvtInfo_AutoCreatedDemEvent_NVM_E_INTEGRITY_FAILED: start-on-event=DemSatellite_0InternalBehavior/GetEventFailed, operation=EvtInfo_AutoCreatedDemEvent_NVM_E_INTEGRITY_FAILED.GetEventFailed
        OpEventGetEventFailed_GetEventFailed_EvtInfo_AutoCreatedDemEvent_NVM_E_LOSS_OF_REDUNDANCY: start-on-event=DemSatellite_0InternalBehavior/GetEventFailed, operation=EvtInfo_AutoCreatedDemEvent_NVM_E_LOSS_OF_REDUNDANCY.GetEventFailed
        OpEventGetEventFailed_GetEventFailed_EvtInfo_AutoCreatedDemEvent_NVM_E_QUEUE_OVERFLOW: start-on-event=DemSatellite_0InternalBehavior/GetEventFailed, operation=EvtInfo_AutoCreatedDemEvent_NVM_E_QUEUE_OVERFLOW.GetEventFailed
        OpEventGetEventFailed_GetEventFailed_EvtInfo_AutoCreatedDemEvent_NVM_E_REQ_FAILED: start-on-event=DemSatellite_0InternalBehavior/GetEventFailed, operation=EvtInfo_AutoCreatedDemEvent_NVM_E_REQ_FAILED.GetEventFailed
        OpEventGetEventFailed_GetEventFailed_EvtInfo_AutoCreatedDemEvent_NVM_E_VERIFY_FAILED: start-on-event=DemSatellite_0InternalBehavior/GetEventFailed, operation=EvtInfo_AutoCreatedDemEvent_NVM_E_VERIFY_FAILED.GetEventFailed
        OpEventGetEventFailed_GetEventFailed_EvtInfo_AutoCreatedDemEvent_NVM_E_WRITE_PROTECTED: start-on-event=DemSatellite_0InternalBehavior/GetEventFailed, operation=EvtInfo_AutoCreatedDemEvent_NVM_E_WRITE_PROTECTED.GetEventFailed
        OpEventGetEventFailed_GetEventFailed_EvtInfo_AutoCreatedDemEvent_NVM_E_WRONG_BLOCK_ID: start-on-event=DemSatellite_0InternalBehavior/GetEventFailed, operation=EvtInfo_AutoCreatedDemEvent_NVM_E_WRONG_BLOCK_ID.GetEventFailed
        OpEventGetEventFailed_GetEventFailed_GeneralEventInfo: start-on-event=DemSatellite_0InternalBehavior/GetEventFailed, operation=GeneralEventInfo.GetEventFailed
        OpEventGetEventTested_GetEventTested_EvtInfo_AutoCreatedDemEvent_NVM_E_INTEGRITY_FAILED: start-on-event=DemSatellite_0InternalBehavior/GetEventTested, operation=EvtInfo_AutoCreatedDemEvent_NVM_E_INTEGRITY_FAILED.GetEventTested
        OpEventGetEventTested_GetEventTested_EvtInfo_AutoCreatedDemEvent_NVM_E_LOSS_OF_REDUNDANCY: start-on-event=DemSatellite_0InternalBehavior/GetEventTested, operation=EvtInfo_AutoCreatedDemEvent_NVM_E_LOSS_OF_REDUNDANCY.GetEventTested
        OpEventGetEventTested_GetEventTested_EvtInfo_AutoCreatedDemEvent_NVM_E_QUEUE_OVERFLOW: start-on-event=DemSatellite_0InternalBehavior/GetEventTested, operation=EvtInfo_AutoCreatedDemEvent_NVM_E_QUEUE_OVERFLOW.GetEventTested
        OpEventGetEventTested_GetEventTested_EvtInfo_AutoCreatedDemEvent_NVM_E_REQ_FAILED: start-on-event=DemSatellite_0InternalBehavior/GetEventTested, operation=EvtInfo_AutoCreatedDemEvent_NVM_E_REQ_FAILED.GetEventTested
        OpEventGetEventTested_GetEventTested_EvtInfo_AutoCreatedDemEvent_NVM_E_VERIFY_FAILED: start-on-event=DemSatellite_0InternalBehavior/GetEventTested, operation=EvtInfo_AutoCreatedDemEvent_NVM_E_VERIFY_FAILED.GetEventTested
        OpEventGetEventTested_GetEventTested_EvtInfo_AutoCreatedDemEvent_NVM_E_WRITE_PROTECTED: start-on-event=DemSatellite_0InternalBehavior/GetEventTested, operation=EvtInfo_AutoCreatedDemEvent_NVM_E_WRITE_PROTECTED.GetEventTested
        OpEventGetEventTested_GetEventTested_EvtInfo_AutoCreatedDemEvent_NVM_E_WRONG_BLOCK_ID: start-on-event=DemSatellite_0InternalBehavior/GetEventTested, operation=EvtInfo_AutoCreatedDemEvent_NVM_E_WRONG_BLOCK_ID.GetEventTested
        OpEventGetEventTested_GetEventTested_GeneralEventInfo: start-on-event=DemSatellite_0InternalBehavior/GetEventTested, operation=GeneralEventInfo.GetEventTested
        OpEventGetDTCOfEvent_GetDTCOfEvent_EvtInfo_AutoCreatedDemEvent_NVM_E_INTEGRITY_FAILED: start-on-event=DemSatellite_0InternalBehavior/GetDTCOfEvent, operation=EvtInfo_AutoCreatedDemEvent_NVM_E_INTEGRITY_FAILED.GetDTCOfEvent
        OpEventGetDTCOfEvent_GetDTCOfEvent_EvtInfo_AutoCreatedDemEvent_NVM_E_LOSS_OF_REDUNDANCY: start-on-event=DemSatellite_0InternalBehavior/GetDTCOfEvent, operation=EvtInfo_AutoCreatedDemEvent_NVM_E_LOSS_OF_REDUNDANCY.GetDTCOfEvent
        OpEventGetDTCOfEvent_GetDTCOfEvent_EvtInfo_AutoCreatedDemEvent_NVM_E_QUEUE_OVERFLOW: start-on-event=DemSatellite_0InternalBehavior/GetDTCOfEvent, operation=EvtInfo_AutoCreatedDemEvent_NVM_E_QUEUE_OVERFLOW.GetDTCOfEvent
        OpEventGetDTCOfEvent_GetDTCOfEvent_EvtInfo_AutoCreatedDemEvent_NVM_E_REQ_FAILED: start-on-event=DemSatellite_0InternalBehavior/GetDTCOfEvent, operation=EvtInfo_AutoCreatedDemEvent_NVM_E_REQ_FAILED.GetDTCOfEvent
        OpEventGetDTCOfEvent_GetDTCOfEvent_EvtInfo_AutoCreatedDemEvent_NVM_E_VERIFY_FAILED: start-on-event=DemSatellite_0InternalBehavior/GetDTCOfEvent, operation=EvtInfo_AutoCreatedDemEvent_NVM_E_VERIFY_FAILED.GetDTCOfEvent
        OpEventGetDTCOfEvent_GetDTCOfEvent_EvtInfo_AutoCreatedDemEvent_NVM_E_WRITE_PROTECTED: start-on-event=DemSatellite_0InternalBehavior/GetDTCOfEvent, operation=EvtInfo_AutoCreatedDemEvent_NVM_E_WRITE_PROTECTED.GetDTCOfEvent
        OpEventGetDTCOfEvent_GetDTCOfEvent_EvtInfo_AutoCreatedDemEvent_NVM_E_WRONG_BLOCK_ID: start-on-event=DemSatellite_0InternalBehavior/GetDTCOfEvent, operation=EvtInfo_AutoCreatedDemEvent_NVM_E_WRONG_BLOCK_ID.GetDTCOfEvent
        OpEventGetDTCOfEvent_GetDTCOfEvent_GeneralEventInfo: start-on-event=DemSatellite_0InternalBehavior/GetDTCOfEvent, operation=GeneralEventInfo.GetDTCOfEvent
        OpEventGetFaultDetectionCounter_GetFaultDetectionCounter_EvtInfo_AutoCreatedDemEvent_NVM_E_INTEGRITY_FAILED: start-on-event=DemSatellite_0InternalBehavior/GetFaultDetectionCounter, operation=EvtInfo_AutoCreatedDemEvent_NVM_E_INTEGRITY_FAILED.GetFaultDetectionCounter
        OpEventGetFaultDetectionCounter_GetFaultDetectionCounter_EvtInfo_AutoCreatedDemEvent_NVM_E_LOSS_OF_REDUNDANCY: start-on-event=DemSatellite_0InternalBehavior/GetFaultDetectionCounter, operation=EvtInfo_AutoCreatedDemEvent_NVM_E_LOSS_OF_REDUNDANCY.GetFaultDetectionCounter
        OpEventGetFaultDetectionCounter_GetFaultDetectionCounter_EvtInfo_AutoCreatedDemEvent_NVM_E_QUEUE_OVERFLOW: start-on-event=DemSatellite_0InternalBehavior/GetFaultDetectionCounter, operation=EvtInfo_AutoCreatedDemEvent_NVM_E_QUEUE_OVERFLOW.GetFaultDetectionCounter
        OpEventGetFaultDetectionCounter_GetFaultDetectionCounter_EvtInfo_AutoCreatedDemEvent_NVM_E_REQ_FAILED: start-on-event=DemSatellite_0InternalBehavior/GetFaultDetectionCounter, operation=EvtInfo_AutoCreatedDemEvent_NVM_E_REQ_FAILED.GetFaultDetectionCounter
        OpEventGetFaultDetectionCounter_GetFaultDetectionCounter_EvtInfo_AutoCreatedDemEvent_NVM_E_VERIFY_FAILED: start-on-event=DemSatellite_0InternalBehavior/GetFaultDetectionCounter, operation=EvtInfo_AutoCreatedDemEvent_NVM_E_VERIFY_FAILED.GetFaultDetectionCounter
        OpEventGetFaultDetectionCounter_GetFaultDetectionCounter_EvtInfo_AutoCreatedDemEvent_NVM_E_WRITE_PROTECTED: start-on-event=DemSatellite_0InternalBehavior/GetFaultDetectionCounter, operation=EvtInfo_AutoCreatedDemEvent_NVM_E_WRITE_PROTECTED.GetFaultDetectionCounter
        OpEventGetFaultDetectionCounter_GetFaultDetectionCounter_EvtInfo_AutoCreatedDemEvent_NVM_E_WRONG_BLOCK_ID: start-on-event=DemSatellite_0InternalBehavior/GetFaultDetectionCounter, operation=EvtInfo_AutoCreatedDemEvent_NVM_E_WRONG_BLOCK_ID.GetFaultDetectionCounter
        OpEventGetFaultDetectionCounter_GetFaultDetectionCounter_GeneralEventInfo: start-on-event=DemSatellite_0InternalBehavior/GetFaultDetectionCounter, operation=GeneralEventInfo.GetFaultDetectionCounter
        OpEventGetEventFreezeFrameDataEx_GetEventFreezeFrameDataEx_EvtInfo_AutoCreatedDemEvent_NVM_E_INTEGRITY_FAILED: start-on-event=DemSatellite_0InternalBehavior/GetEventFreezeFrameDataEx, operation=EvtInfo_AutoCreatedDemEvent_NVM_E_INTEGRITY_FAILED.GetEventFreezeFrameDataEx
        OpEventGetEventFreezeFrameDataEx_GetEventFreezeFrameDataEx_EvtInfo_AutoCreatedDemEvent_NVM_E_LOSS_OF_REDUNDANCY: start-on-event=DemSatellite_0InternalBehavior/GetEventFreezeFrameDataEx, operation=EvtInfo_AutoCreatedDemEvent_NVM_E_LOSS_OF_REDUNDANCY.GetEventFreezeFrameDataEx
        OpEventGetEventFreezeFrameDataEx_GetEventFreezeFrameDataEx_EvtInfo_AutoCreatedDemEvent_NVM_E_QUEUE_OVERFLOW: start-on-event=DemSatellite_0InternalBehavior/GetEventFreezeFrameDataEx, operation=EvtInfo_AutoCreatedDemEvent_NVM_E_QUEUE_OVERFLOW.GetEventFreezeFrameDataEx
        OpEventGetEventFreezeFrameDataEx_GetEventFreezeFrameDataEx_EvtInfo_AutoCreatedDemEvent_NVM_E_REQ_FAILED: start-on-event=DemSatellite_0InternalBehavior/GetEventFreezeFrameDataEx, operation=EvtInfo_AutoCreatedDemEvent_NVM_E_REQ_FAILED.GetEventFreezeFrameDataEx
        OpEventGetEventFreezeFrameDataEx_GetEventFreezeFrameDataEx_EvtInfo_AutoCreatedDemEvent_NVM_E_VERIFY_FAILED: start-on-event=DemSatellite_0InternalBehavior/GetEventFreezeFrameDataEx, operation=EvtInfo_AutoCreatedDemEvent_NVM_E_VERIFY_FAILED.GetEventFreezeFrameDataEx
        OpEventGetEventFreezeFrameDataEx_GetEventFreezeFrameDataEx_EvtInfo_AutoCreatedDemEvent_NVM_E_WRITE_PROTECTED: start-on-event=DemSatellite_0InternalBehavior/GetEventFreezeFrameDataEx, operation=EvtInfo_AutoCreatedDemEvent_NVM_E_WRITE_PROTECTED.GetEventFreezeFrameDataEx
        OpEventGetEventFreezeFrameDataEx_GetEventFreezeFrameDataEx_EvtInfo_AutoCreatedDemEvent_NVM_E_WRONG_BLOCK_ID: start-on-event=DemSatellite_0InternalBehavior/GetEventFreezeFrameDataEx, operation=EvtInfo_AutoCreatedDemEvent_NVM_E_WRONG_BLOCK_ID.GetEventFreezeFrameDataEx
        OpEventGetEventFreezeFrameDataEx_GetEventFreezeFrameDataEx_GeneralEventInfo: start-on-event=DemSatellite_0InternalBehavior/GetEventFreezeFrameDataEx, operation=GeneralEventInfo.GetEventFreezeFrameDataEx
        OpEventGetEventExtendedDataRecordEx_GetEventExtendedDataRecordEx_EvtInfo_AutoCreatedDemEvent_NVM_E_INTEGRITY_FAILED: start-on-event=DemSatellite_0InternalBehavior/GetEventExtendedDataRecordEx, operation=EvtInfo_AutoCreatedDemEvent_NVM_E_INTEGRITY_FAILED.GetEventExtendedDataRecordEx
        OpEventGetEventExtendedDataRecordEx_GetEventExtendedDataRecordEx_EvtInfo_AutoCreatedDemEvent_NVM_E_LOSS_OF_REDUNDANCY: start-on-event=DemSatellite_0InternalBehavior/GetEventExtendedDataRecordEx, operation=EvtInfo_AutoCreatedDemEvent_NVM_E_LOSS_OF_REDUNDANCY.GetEventExtendedDataRecordEx
        OpEventGetEventExtendedDataRecordEx_GetEventExtendedDataRecordEx_EvtInfo_AutoCreatedDemEvent_NVM_E_QUEUE_OVERFLOW: start-on-event=DemSatellite_0InternalBehavior/GetEventExtendedDataRecordEx, operation=EvtInfo_AutoCreatedDemEvent_NVM_E_QUEUE_OVERFLOW.GetEventExtendedDataRecordEx
        OpEventGetEventExtendedDataRecordEx_GetEventExtendedDataRecordEx_EvtInfo_AutoCreatedDemEvent_NVM_E_REQ_FAILED: start-on-event=DemSatellite_0InternalBehavior/GetEventExtendedDataRecordEx, operation=EvtInfo_AutoCreatedDemEvent_NVM_E_REQ_FAILED.GetEventExtendedDataRecordEx
        OpEventGetEventExtendedDataRecordEx_GetEventExtendedDataRecordEx_EvtInfo_AutoCreatedDemEvent_NVM_E_VERIFY_FAILED: start-on-event=DemSatellite_0InternalBehavior/GetEventExtendedDataRecordEx, operation=EvtInfo_AutoCreatedDemEvent_NVM_E_VERIFY_FAILED.GetEventExtendedDataRecordEx
        OpEventGetEventExtendedDataRecordEx_GetEventExtendedDataRecordEx_EvtInfo_AutoCreatedDemEvent_NVM_E_WRITE_PROTECTED: start-on-event=DemSatellite_0InternalBehavior/GetEventExtendedDataRecordEx, operation=EvtInfo_AutoCreatedDemEvent_NVM_E_WRITE_PROTECTED.GetEventExtendedDataRecordEx
        OpEventGetEventExtendedDataRecordEx_GetEventExtendedDataRecordEx_EvtInfo_AutoCreatedDemEvent_NVM_E_WRONG_BLOCK_ID: start-on-event=DemSatellite_0InternalBehavior/GetEventExtendedDataRecordEx, operation=EvtInfo_AutoCreatedDemEvent_NVM_E_WRONG_BLOCK_ID.GetEventExtendedDataRecordEx
        OpEventGetEventExtendedDataRecordEx_GetEventExtendedDataRecordEx_GeneralEventInfo: start-on-event=DemSatellite_0InternalBehavior/GetEventExtendedDataRecordEx, operation=GeneralEventInfo.GetEventExtendedDataRecordEx
        OpEventGetEventEnableCondition_GetEventEnableCondition_EvtInfo_AutoCreatedDemEvent_NVM_E_INTEGRITY_FAILED: start-on-event=DemSatellite_0InternalBehavior/GetEventEnableCondition, operation=EvtInfo_AutoCreatedDemEvent_NVM_E_INTEGRITY_FAILED.GetEventEnableCondition
        OpEventGetEventEnableCondition_GetEventEnableCondition_EvtInfo_AutoCreatedDemEvent_NVM_E_LOSS_OF_REDUNDANCY: start-on-event=DemSatellite_0InternalBehavior/GetEventEnableCondition, operation=EvtInfo_AutoCreatedDemEvent_NVM_E_LOSS_OF_REDUNDANCY.GetEventEnableCondition
        OpEventGetEventEnableCondition_GetEventEnableCondition_EvtInfo_AutoCreatedDemEvent_NVM_E_QUEUE_OVERFLOW: start-on-event=DemSatellite_0InternalBehavior/GetEventEnableCondition, operation=EvtInfo_AutoCreatedDemEvent_NVM_E_QUEUE_OVERFLOW.GetEventEnableCondition
        OpEventGetEventEnableCondition_GetEventEnableCondition_EvtInfo_AutoCreatedDemEvent_NVM_E_REQ_FAILED: start-on-event=DemSatellite_0InternalBehavior/GetEventEnableCondition, operation=EvtInfo_AutoCreatedDemEvent_NVM_E_REQ_FAILED.GetEventEnableCondition
        OpEventGetEventEnableCondition_GetEventEnableCondition_EvtInfo_AutoCreatedDemEvent_NVM_E_VERIFY_FAILED: start-on-event=DemSatellite_0InternalBehavior/GetEventEnableCondition, operation=EvtInfo_AutoCreatedDemEvent_NVM_E_VERIFY_FAILED.GetEventEnableCondition
        OpEventGetEventEnableCondition_GetEventEnableCondition_EvtInfo_AutoCreatedDemEvent_NVM_E_WRITE_PROTECTED: start-on-event=DemSatellite_0InternalBehavior/GetEventEnableCondition, operation=EvtInfo_AutoCreatedDemEvent_NVM_E_WRITE_PROTECTED.GetEventEnableCondition
        OpEventGetEventEnableCondition_GetEventEnableCondition_EvtInfo_AutoCreatedDemEvent_NVM_E_WRONG_BLOCK_ID: start-on-event=DemSatellite_0InternalBehavior/GetEventEnableCondition, operation=EvtInfo_AutoCreatedDemEvent_NVM_E_WRONG_BLOCK_ID.GetEventEnableCondition
        OpEventGetEventEnableCondition_GetEventEnableCondition_GeneralEventInfo: start-on-event=DemSatellite_0InternalBehavior/GetEventEnableCondition, operation=GeneralEventInfo.GetEventEnableCondition
        OpEventGetDebouncingOfEvent_GetDebouncingOfEvent_EvtInfo_AutoCreatedDemEvent_NVM_E_INTEGRITY_FAILED: start-on-event=DemSatellite_0InternalBehavior/GetDebouncingOfEvent, operation=EvtInfo_AutoCreatedDemEvent_NVM_E_INTEGRITY_FAILED.GetDebouncingOfEvent
        OpEventGetDebouncingOfEvent_GetDebouncingOfEvent_EvtInfo_AutoCreatedDemEvent_NVM_E_LOSS_OF_REDUNDANCY: start-on-event=DemSatellite_0InternalBehavior/GetDebouncingOfEvent, operation=EvtInfo_AutoCreatedDemEvent_NVM_E_LOSS_OF_REDUNDANCY.GetDebouncingOfEvent
        OpEventGetDebouncingOfEvent_GetDebouncingOfEvent_EvtInfo_AutoCreatedDemEvent_NVM_E_QUEUE_OVERFLOW: start-on-event=DemSatellite_0InternalBehavior/GetDebouncingOfEvent, operation=EvtInfo_AutoCreatedDemEvent_NVM_E_QUEUE_OVERFLOW.GetDebouncingOfEvent
        OpEventGetDebouncingOfEvent_GetDebouncingOfEvent_EvtInfo_AutoCreatedDemEvent_NVM_E_REQ_FAILED: start-on-event=DemSatellite_0InternalBehavior/GetDebouncingOfEvent, operation=EvtInfo_AutoCreatedDemEvent_NVM_E_REQ_FAILED.GetDebouncingOfEvent
        OpEventGetDebouncingOfEvent_GetDebouncingOfEvent_EvtInfo_AutoCreatedDemEvent_NVM_E_VERIFY_FAILED: start-on-event=DemSatellite_0InternalBehavior/GetDebouncingOfEvent, operation=EvtInfo_AutoCreatedDemEvent_NVM_E_VERIFY_FAILED.GetDebouncingOfEvent
        OpEventGetDebouncingOfEvent_GetDebouncingOfEvent_EvtInfo_AutoCreatedDemEvent_NVM_E_WRITE_PROTECTED: start-on-event=DemSatellite_0InternalBehavior/GetDebouncingOfEvent, operation=EvtInfo_AutoCreatedDemEvent_NVM_E_WRITE_PROTECTED.GetDebouncingOfEvent
        OpEventGetDebouncingOfEvent_GetDebouncingOfEvent_EvtInfo_AutoCreatedDemEvent_NVM_E_WRONG_BLOCK_ID: start-on-event=DemSatellite_0InternalBehavior/GetDebouncingOfEvent, operation=EvtInfo_AutoCreatedDemEvent_NVM_E_WRONG_BLOCK_ID.GetDebouncingOfEvent
        OpEventGetDebouncingOfEvent_GetDebouncingOfEvent_GeneralEventInfo: start-on-event=DemSatellite_0InternalBehavior/GetDebouncingOfEvent, operation=GeneralEventInfo.GetDebouncingOfEvent
        OpEventGetMonitorStatus_GetMonitorStatus_EvtInfo_AutoCreatedDemEvent_NVM_E_INTEGRITY_FAILED: start-on-event=DemSatellite_0InternalBehavior/GetMonitorStatus, operation=EvtInfo_AutoCreatedDemEvent_NVM_E_INTEGRITY_FAILED.GetMonitorStatus
        OpEventGetMonitorStatus_GetMonitorStatus_EvtInfo_AutoCreatedDemEvent_NVM_E_LOSS_OF_REDUNDANCY: start-on-event=DemSatellite_0InternalBehavior/GetMonitorStatus, operation=EvtInfo_AutoCreatedDemEvent_NVM_E_LOSS_OF_REDUNDANCY.GetMonitorStatus
        OpEventGetMonitorStatus_GetMonitorStatus_EvtInfo_AutoCreatedDemEvent_NVM_E_QUEUE_OVERFLOW: start-on-event=DemSatellite_0InternalBehavior/GetMonitorStatus, operation=EvtInfo_AutoCreatedDemEvent_NVM_E_QUEUE_OVERFLOW.GetMonitorStatus
        OpEventGetMonitorStatus_GetMonitorStatus_EvtInfo_AutoCreatedDemEvent_NVM_E_REQ_FAILED: start-on-event=DemSatellite_0InternalBehavior/GetMonitorStatus, operation=EvtInfo_AutoCreatedDemEvent_NVM_E_REQ_FAILED.GetMonitorStatus
        OpEventGetMonitorStatus_GetMonitorStatus_EvtInfo_AutoCreatedDemEvent_NVM_E_VERIFY_FAILED: start-on-event=DemSatellite_0InternalBehavior/GetMonitorStatus, operation=EvtInfo_AutoCreatedDemEvent_NVM_E_VERIFY_FAILED.GetMonitorStatus
        OpEventGetMonitorStatus_GetMonitorStatus_EvtInfo_AutoCreatedDemEvent_NVM_E_WRITE_PROTECTED: start-on-event=DemSatellite_0InternalBehavior/GetMonitorStatus, operation=EvtInfo_AutoCreatedDemEvent_NVM_E_WRITE_PROTECTED.GetMonitorStatus
        OpEventGetMonitorStatus_GetMonitorStatus_EvtInfo_AutoCreatedDemEvent_NVM_E_WRONG_BLOCK_ID: start-on-event=DemSatellite_0InternalBehavior/GetMonitorStatus, operation=EvtInfo_AutoCreatedDemEvent_NVM_E_WRONG_BLOCK_ID.GetMonitorStatus
        OpEventGetMonitorStatus_GetMonitorStatus_GeneralEventInfo: start-on-event=DemSatellite_0InternalBehavior/GetMonitorStatus, operation=GeneralEventInfo.GetMonitorStatus
        OpEventGetEventUdsStatus_GetEventUdsStatus_EvtInfo_AutoCreatedDemEvent_EcuMConfiguration_ECUM_E_ALL_RUN_REQUESTS_KILLED: start-on-event=DemSatellite_0InternalBehavior/GetEventUdsStatus, operation=EvtInfo_AutoCreatedDemEvent_EcuMConfiguration_ECUM_E_ALL_RUN_REQUESTS_KILLED.GetEventUdsStatus
        OpEventGetEventUdsStatus_GetEventUdsStatus_EvtInfo_AutoCreatedDemEvent_EcuMConfiguration_ECUM_E_CONFIGURATION_DATA_INCONSISTENT: start-on-event=DemSatellite_0InternalBehavior/GetEventUdsStatus, operation=EvtInfo_AutoCreatedDemEvent_EcuMConfiguration_ECUM_E_CONFIGURATION_DATA_INCONSISTENT.GetEventUdsStatus
        OpEventGetEventUdsStatus_GetEventUdsStatus_EvtInfo_AutoCreatedDemEvent_EcuMConfiguration_ECUM_E_RAM_CHECK_FAILED: start-on-event=DemSatellite_0InternalBehavior/GetEventUdsStatus, operation=EvtInfo_AutoCreatedDemEvent_EcuMConfiguration_ECUM_E_RAM_CHECK_FAILED.GetEventUdsStatus
        OpEventGetEventUdsStatus_GetEventUdsStatus_EvtInfo_AutoCreatedDemEvent_EcuMConfiguration_ECUM_E_IMPROPER_CALLER: start-on-event=DemSatellite_0InternalBehavior/GetEventUdsStatus, operation=EvtInfo_AutoCreatedDemEvent_EcuMConfiguration_ECUM_E_IMPROPER_CALLER.GetEventUdsStatus
        OpEventGetEventStatus_GetEventStatus_EvtInfo_AutoCreatedDemEvent_EcuMConfiguration_ECUM_E_ALL_RUN_REQUESTS_KILLED: start-on-event=DemSatellite_0InternalBehavior/GetEventStatus, operation=EvtInfo_AutoCreatedDemEvent_EcuMConfiguration_ECUM_E_ALL_RUN_REQUESTS_KILLED.GetEventStatus
        OpEventGetEventStatus_GetEventStatus_EvtInfo_AutoCreatedDemEvent_EcuMConfiguration_ECUM_E_CONFIGURATION_DATA_INCONSISTENT: start-on-event=DemSatellite_0InternalBehavior/GetEventStatus, operation=EvtInfo_AutoCreatedDemEvent_EcuMConfiguration_ECUM_E_CONFIGURATION_DATA_INCONSISTENT.GetEventStatus
        OpEventGetEventStatus_GetEventStatus_EvtInfo_AutoCreatedDemEvent_EcuMConfiguration_ECUM_E_RAM_CHECK_FAILED: start-on-event=DemSatellite_0InternalBehavior/GetEventStatus, operation=EvtInfo_AutoCreatedDemEvent_EcuMConfiguration_ECUM_E_RAM_CHECK_FAILED.GetEventStatus
        OpEventGetEventStatus_GetEventStatus_EvtInfo_AutoCreatedDemEvent_EcuMConfiguration_ECUM_E_IMPROPER_CALLER: start-on-event=DemSatellite_0InternalBehavior/GetEventStatus, operation=EvtInfo_AutoCreatedDemEvent_EcuMConfiguration_ECUM_E_IMPROPER_CALLER.GetEventStatus
        OpEventGetEventFailed_GetEventFailed_EvtInfo_AutoCreatedDemEvent_EcuMConfiguration_ECUM_E_ALL_RUN_REQUESTS_KILLED: start-on-event=DemSatellite_0InternalBehavior/GetEventFailed, operation=EvtInfo_AutoCreatedDemEvent_EcuMConfiguration_ECUM_E_ALL_RUN_REQUESTS_KILLED.GetEventFailed
        OpEventGetEventFailed_GetEventFailed_EvtInfo_AutoCreatedDemEvent_EcuMConfiguration_ECUM_E_CONFIGURATION_DATA_INCONSISTENT: start-on-event=DemSatellite_0InternalBehavior/GetEventFailed, operation=EvtInfo_AutoCreatedDemEvent_EcuMConfiguration_ECUM_E_CONFIGURATION_DATA_INCONSISTENT.GetEventFailed
        OpEventGetEventFailed_GetEventFailed_EvtInfo_AutoCreatedDemEvent_EcuMConfiguration_ECUM_E_RAM_CHECK_FAILED: start-on-event=DemSatellite_0InternalBehavior/GetEventFailed, operation=EvtInfo_AutoCreatedDemEvent_EcuMConfiguration_ECUM_E_RAM_CHECK_FAILED.GetEventFailed
        OpEventGetEventFailed_GetEventFailed_EvtInfo_AutoCreatedDemEvent_EcuMConfiguration_ECUM_E_IMPROPER_CALLER: start-on-event=DemSatellite_0InternalBehavior/GetEventFailed, operation=EvtInfo_AutoCreatedDemEvent_EcuMConfiguration_ECUM_E_IMPROPER_CALLER.GetEventFailed
        OpEventGetEventTested_GetEventTested_EvtInfo_AutoCreatedDemEvent_EcuMConfiguration_ECUM_E_ALL_RUN_REQUESTS_KILLED: start-on-event=DemSatellite_0InternalBehavior/GetEventTested, operation=EvtInfo_AutoCreatedDemEvent_EcuMConfiguration_ECUM_E_ALL_RUN_REQUESTS_KILLED.GetEventTested
        OpEventGetEventTested_GetEventTested_EvtInfo_AutoCreatedDemEvent_EcuMConfiguration_ECUM_E_CONFIGURATION_DATA_INCONSISTENT: start-on-event=DemSatellite_0InternalBehavior/GetEventTested, operation=EvtInfo_AutoCreatedDemEvent_EcuMConfiguration_ECUM_E_CONFIGURATION_DATA_INCONSISTENT.GetEventTested
        OpEventGetEventTested_GetEventTested_EvtInfo_AutoCreatedDemEvent_EcuMConfiguration_ECUM_E_RAM_CHECK_FAILED: start-on-event=DemSatellite_0InternalBehavior/GetEventTested, operation=EvtInfo_AutoCreatedDemEvent_EcuMConfiguration_ECUM_E_RAM_CHECK_FAILED.GetEventTested
        OpEventGetEventTested_GetEventTested_EvtInfo_AutoCreatedDemEvent_EcuMConfiguration_ECUM_E_IMPROPER_CALLER: start-on-event=DemSatellite_0InternalBehavior/GetEventTested, operation=EvtInfo_AutoCreatedDemEvent_EcuMConfiguration_ECUM_E_IMPROPER_CALLER.GetEventTested
        OpEventGetDTCOfEvent_GetDTCOfEvent_EvtInfo_AutoCreatedDemEvent_EcuMConfiguration_ECUM_E_ALL_RUN_REQUESTS_KILLED: start-on-event=DemSatellite_0InternalBehavior/GetDTCOfEvent, operation=EvtInfo_AutoCreatedDemEvent_EcuMConfiguration_ECUM_E_ALL_RUN_REQUESTS_KILLED.GetDTCOfEvent
        OpEventGetDTCOfEvent_GetDTCOfEvent_EvtInfo_AutoCreatedDemEvent_EcuMConfiguration_ECUM_E_CONFIGURATION_DATA_INCONSISTENT: start-on-event=DemSatellite_0InternalBehavior/GetDTCOfEvent, operation=EvtInfo_AutoCreatedDemEvent_EcuMConfiguration_ECUM_E_CONFIGURATION_DATA_INCONSISTENT.GetDTCOfEvent
        OpEventGetDTCOfEvent_GetDTCOfEvent_EvtInfo_AutoCreatedDemEvent_EcuMConfiguration_ECUM_E_RAM_CHECK_FAILED: start-on-event=DemSatellite_0InternalBehavior/GetDTCOfEvent, operation=EvtInfo_AutoCreatedDemEvent_EcuMConfiguration_ECUM_E_RAM_CHECK_FAILED.GetDTCOfEvent
        OpEventGetDTCOfEvent_GetDTCOfEvent_EvtInfo_AutoCreatedDemEvent_EcuMConfiguration_ECUM_E_IMPROPER_CALLER: start-on-event=DemSatellite_0InternalBehavior/GetDTCOfEvent, operation=EvtInfo_AutoCreatedDemEvent_EcuMConfiguration_ECUM_E_IMPROPER_CALLER.GetDTCOfEvent
        OpEventGetFaultDetectionCounter_GetFaultDetectionCounter_EvtInfo_AutoCreatedDemEvent_EcuMConfiguration_ECUM_E_ALL_RUN_R_5c1d7bad: start-on-event=DemSatellite_0InternalBehavior/GetFaultDetectionCounter, operation=EvtInfo_AutoCreatedDemEvent_EcuMConfiguration_ECUM_E_ALL_RUN_REQUESTS_KILLED.GetFaultDetectionCounter
        OpEventGetFaultDetectionCounter_GetFaultDetectionCounter_EvtInfo_AutoCreatedDemEvent_EcuMConfiguration_ECUM_E_CONFIGURA_55d3b4f6: start-on-event=DemSatellite_0InternalBehavior/GetFaultDetectionCounter, operation=EvtInfo_AutoCreatedDemEvent_EcuMConfiguration_ECUM_E_CONFIGURATION_DATA_INCONSISTENT.GetFaultDetectionCounter
        OpEventGetFaultDetectionCounter_GetFaultDetectionCounter_EvtInfo_AutoCreatedDemEvent_EcuMConfiguration_ECUM_E_RAM_CHECK_FAILED: start-on-event=DemSatellite_0InternalBehavior/GetFaultDetectionCounter, operation=EvtInfo_AutoCreatedDemEvent_EcuMConfiguration_ECUM_E_RAM_CHECK_FAILED.GetFaultDetectionCounter
        OpEventGetFaultDetectionCounter_GetFaultDetectionCounter_EvtInfo_AutoCreatedDemEvent_EcuMConfiguration_ECUM_E_IMPROPER_CALLER: start-on-event=DemSatellite_0InternalBehavior/GetFaultDetectionCounter, operation=EvtInfo_AutoCreatedDemEvent_EcuMConfiguration_ECUM_E_IMPROPER_CALLER.GetFaultDetectionCounter
        OpEventGetEventFreezeFrameDataEx_GetEventFreezeFrameDataEx_EvtInfo_AutoCreatedDemEvent_EcuMConfiguration_ECUM_E_ALL_RUN_993f76de: start-on-event=DemSatellite_0InternalBehavior/GetEventFreezeFrameDataEx, operation=EvtInfo_AutoCreatedDemEvent_EcuMConfiguration_ECUM_E_ALL_RUN_REQUESTS_KILLED.GetEventFreezeFrameDataEx
        OpEventGetEventFreezeFrameDataEx_GetEventFreezeFrameDataEx_EvtInfo_AutoCreatedDemEvent_EcuMConfiguration_ECUM_E_CONFIGU_7d4a80d3: start-on-event=DemSatellite_0InternalBehavior/GetEventFreezeFrameDataEx, operation=EvtInfo_AutoCreatedDemEvent_EcuMConfiguration_ECUM_E_CONFIGURATION_DATA_INCONSISTENT.GetEventFreezeFrameDataEx
        OpEventGetEventFreezeFrameDataEx_GetEventFreezeFrameDataEx_EvtInfo_AutoCreatedDemEvent_EcuMConfiguration_ECUM_E_RAM_CHECK_FAILED: start-on-event=DemSatellite_0InternalBehavior/GetEventFreezeFrameDataEx, operation=EvtInfo_AutoCreatedDemEvent_EcuMConfiguration_ECUM_E_RAM_CHECK_FAILED.GetEventFreezeFrameDataEx
        OpEventGetEventFreezeFrameDataEx_GetEventFreezeFrameDataEx_EvtInfo_AutoCreatedDemEvent_EcuMConfiguration_ECUM_E_IMPROPER_CALLER: start-on-event=DemSatellite_0InternalBehavior/GetEventFreezeFrameDataEx, operation=EvtInfo_AutoCreatedDemEvent_EcuMConfiguration_ECUM_E_IMPROPER_CALLER.GetEventFreezeFrameDataEx
        OpEventGetEventExtendedDataRecordEx_GetEventExtendedDataRecordEx_EvtInfo_AutoCreatedDemEvent_EcuMConfiguration_ECUM_E_A_6cc04a27: start-on-event=DemSatellite_0InternalBehavior/GetEventExtendedDataRecordEx, operation=EvtInfo_AutoCreatedDemEvent_EcuMConfiguration_ECUM_E_ALL_RUN_REQUESTS_KILLED.GetEventExtendedDataRecordEx
        OpEventGetEventExtendedDataRecordEx_GetEventExtendedDataRecordEx_EvtInfo_AutoCreatedDemEvent_EcuMConfiguration_ECUM_E_C_96bd3475: start-on-event=DemSatellite_0InternalBehavior/GetEventExtendedDataRecordEx, operation=EvtInfo_AutoCreatedDemEvent_EcuMConfiguration_ECUM_E_CONFIGURATION_DATA_INCONSISTENT.GetEventExtendedDataRecordEx
        OpEventGetEventExtendedDataRecordEx_GetEventExtendedDataRecordEx_EvtInfo_AutoCreatedDemEvent_EcuMConfiguration_ECUM_E_R_25bd882a: start-on-event=DemSatellite_0InternalBehavior/GetEventExtendedDataRecordEx, operation=EvtInfo_AutoCreatedDemEvent_EcuMConfiguration_ECUM_E_RAM_CHECK_FAILED.GetEventExtendedDataRecordEx
        OpEventGetEventExtendedDataRecordEx_GetEventExtendedDataRecordEx_EvtInfo_AutoCreatedDemEvent_EcuMConfiguration_ECUM_E_I_7db075fd: start-on-event=DemSatellite_0InternalBehavior/GetEventExtendedDataRecordEx, operation=EvtInfo_AutoCreatedDemEvent_EcuMConfiguration_ECUM_E_IMPROPER_CALLER.GetEventExtendedDataRecordEx
        OpEventGetEventEnableCondition_GetEventEnableCondition_EvtInfo_AutoCreatedDemEvent_EcuMConfiguration_ECUM_E_ALL_RUN_REQ_5b1f807c: start-on-event=DemSatellite_0InternalBehavior/GetEventEnableCondition, operation=EvtInfo_AutoCreatedDemEvent_EcuMConfiguration_ECUM_E_ALL_RUN_REQUESTS_KILLED.GetEventEnableCondition
        OpEventGetEventEnableCondition_GetEventEnableCondition_EvtInfo_AutoCreatedDemEvent_EcuMConfiguration_ECUM_E_CONFIGURATI_06f5d14c: start-on-event=DemSatellite_0InternalBehavior/GetEventEnableCondition, operation=EvtInfo_AutoCreatedDemEvent_EcuMConfiguration_ECUM_E_CONFIGURATION_DATA_INCONSISTENT.GetEventEnableCondition
        OpEventGetEventEnableCondition_GetEventEnableCondition_EvtInfo_AutoCreatedDemEvent_EcuMConfiguration_ECUM_E_RAM_CHECK_FAILED: start-on-event=DemSatellite_0InternalBehavior/GetEventEnableCondition, operation=EvtInfo_AutoCreatedDemEvent_EcuMConfiguration_ECUM_E_RAM_CHECK_FAILED.GetEventEnableCondition
        OpEventGetEventEnableCondition_GetEventEnableCondition_EvtInfo_AutoCreatedDemEvent_EcuMConfiguration_ECUM_E_IMPROPER_CALLER: start-on-event=DemSatellite_0InternalBehavior/GetEventEnableCondition, operation=EvtInfo_AutoCreatedDemEvent_EcuMConfiguration_ECUM_E_IMPROPER_CALLER.GetEventEnableCondition
        OpEventGetDebouncingOfEvent_GetDebouncingOfEvent_EvtInfo_AutoCreatedDemEvent_EcuMConfiguration_ECUM_E_ALL_RUN_REQUESTS_KILLED: start-on-event=DemSatellite_0InternalBehavior/GetDebouncingOfEvent, operation=EvtInfo_AutoCreatedDemEvent_EcuMConfiguration_ECUM_E_ALL_RUN_REQUESTS_KILLED.GetDebouncingOfEvent
        OpEventGetDebouncingOfEvent_GetDebouncingOfEvent_EvtInfo_AutoCreatedDemEvent_EcuMConfiguration_ECUM_E_CONFIGURATION_DAT_7642b2c3: start-on-event=DemSatellite_0InternalBehavior/GetDebouncingOfEvent, operation=EvtInfo_AutoCreatedDemEvent_EcuMConfiguration_ECUM_E_CONFIGURATION_DATA_INCONSISTENT.GetDebouncingOfEvent
        OpEventGetDebouncingOfEvent_GetDebouncingOfEvent_EvtInfo_AutoCreatedDemEvent_EcuMConfiguration_ECUM_E_RAM_CHECK_FAILED: start-on-event=DemSatellite_0InternalBehavior/GetDebouncingOfEvent, operation=EvtInfo_AutoCreatedDemEvent_EcuMConfiguration_ECUM_E_RAM_CHECK_FAILED.GetDebouncingOfEvent
        OpEventGetDebouncingOfEvent_GetDebouncingOfEvent_EvtInfo_AutoCreatedDemEvent_EcuMConfiguration_ECUM_E_IMPROPER_CALLER: start-on-event=DemSatellite_0InternalBehavior/GetDebouncingOfEvent, operation=EvtInfo_AutoCreatedDemEvent_EcuMConfiguration_ECUM_E_IMPROPER_CALLER.GetDebouncingOfEvent
        OpEventGetMonitorStatus_GetMonitorStatus_EvtInfo_AutoCreatedDemEvent_EcuMConfiguration_ECUM_E_ALL_RUN_REQUESTS_KILLED: start-on-event=DemSatellite_0InternalBehavior/GetMonitorStatus, operation=EvtInfo_AutoCreatedDemEvent_EcuMConfiguration_ECUM_E_ALL_RUN_REQUESTS_KILLED.GetMonitorStatus
        OpEventGetMonitorStatus_GetMonitorStatus_EvtInfo_AutoCreatedDemEvent_EcuMConfiguration_ECUM_E_CONFIGURATION_DATA_INCONSISTENT: start-on-event=DemSatellite_0InternalBehavior/GetMonitorStatus, operation=EvtInfo_AutoCreatedDemEvent_EcuMConfiguration_ECUM_E_CONFIGURATION_DATA_INCONSISTENT.GetMonitorStatus
        OpEventGetMonitorStatus_GetMonitorStatus_EvtInfo_AutoCreatedDemEvent_EcuMConfiguration_ECUM_E_RAM_CHECK_FAILED: start-on-event=DemSatellite_0InternalBehavior/GetMonitorStatus, operation=EvtInfo_AutoCreatedDemEvent_EcuMConfiguration_ECUM_E_RAM_CHECK_FAILED.GetMonitorStatus
        OpEventGetMonitorStatus_GetMonitorStatus_EvtInfo_AutoCreatedDemEvent_EcuMConfiguration_ECUM_E_IMPROPER_CALLER: start-on-event=DemSatellite_0InternalBehavior/GetMonitorStatus, operation=EvtInfo_AutoCreatedDemEvent_EcuMConfiguration_ECUM_E_IMPROPER_CALLER.GetMonitorStatus
        OpEventGetEventUdsStatus_GetEventUdsStatus_EvtInfo_DTC_0x000002: start-on-event=DemSatellite_0InternalBehavior/GetEventUdsStatus, operation=EvtInfo_DTC_0x000002.GetEventUdsStatus
        OpEventGetEventUdsStatus_GetEventUdsStatus_Event_DTC_0x000002: start-on-event=DemSatellite_0InternalBehavior/GetEventUdsStatus, operation=Event_DTC_0x000002.GetEventUdsStatus
        OpEventGetEventStatus_GetEventStatus_EvtInfo_DTC_0x000002: start-on-event=DemSatellite_0InternalBehavior/GetEventStatus, operation=EvtInfo_DTC_0x000002.GetEventStatus
        OpEventGetEventStatus_GetEventStatus_Event_DTC_0x000002: start-on-event=DemSatellite_0InternalBehavior/GetEventStatus, operation=Event_DTC_0x000002.GetEventStatus
        OpEventGetEventFailed_GetEventFailed_EvtInfo_DTC_0x000002: start-on-event=DemSatellite_0InternalBehavior/GetEventFailed, operation=EvtInfo_DTC_0x000002.GetEventFailed
        OpEventGetEventFailed_GetEventFailed_Event_DTC_0x000002: start-on-event=DemSatellite_0InternalBehavior/GetEventFailed, operation=Event_DTC_0x000002.GetEventFailed
        OpEventGetEventTested_GetEventTested_EvtInfo_DTC_0x000002: start-on-event=DemSatellite_0InternalBehavior/GetEventTested, operation=EvtInfo_DTC_0x000002.GetEventTested
        OpEventGetEventTested_GetEventTested_Event_DTC_0x000002: start-on-event=DemSatellite_0InternalBehavior/GetEventTested, operation=Event_DTC_0x000002.GetEventTested
        OpEventGetDTCOfEvent_GetDTCOfEvent_EvtInfo_DTC_0x000002: start-on-event=DemSatellite_0InternalBehavior/GetDTCOfEvent, operation=EvtInfo_DTC_0x000002.GetDTCOfEvent
        OpEventGetDTCOfEvent_GetDTCOfEvent_Event_DTC_0x000002: start-on-event=DemSatellite_0InternalBehavior/GetDTCOfEvent, operation=Event_DTC_0x000002.GetDTCOfEvent
        OpEventGetFaultDetectionCounter_GetFaultDetectionCounter_EvtInfo_DTC_0x000002: start-on-event=DemSatellite_0InternalBehavior/GetFaultDetectionCounter, operation=EvtInfo_DTC_0x000002.GetFaultDetectionCounter
        OpEventGetFaultDetectionCounter_GetFaultDetectionCounter_Event_DTC_0x000002: start-on-event=DemSatellite_0InternalBehavior/GetFaultDetectionCounter, operation=Event_DTC_0x000002.GetFaultDetectionCounter
        OpEventGetEventFreezeFrameDataEx_GetEventFreezeFrameDataEx_EvtInfo_DTC_0x000002: start-on-event=DemSatellite_0InternalBehavior/GetEventFreezeFrameDataEx, operation=EvtInfo_DTC_0x000002.GetEventFreezeFrameDataEx
        OpEventGetEventFreezeFrameDataEx_GetEventFreezeFrameDataEx_Event_DTC_0x000002: start-on-event=DemSatellite_0InternalBehavior/GetEventFreezeFrameDataEx, operation=Event_DTC_0x000002.GetEventFreezeFrameDataEx
        OpEventGetEventExtendedDataRecordEx_GetEventExtendedDataRecordEx_EvtInfo_DTC_0x000002: start-on-event=DemSatellite_0InternalBehavior/GetEventExtendedDataRecordEx, operation=EvtInfo_DTC_0x000002.GetEventExtendedDataRecordEx
        OpEventGetEventExtendedDataRecordEx_GetEventExtendedDataRecordEx_Event_DTC_0x000002: start-on-event=DemSatellite_0InternalBehavior/GetEventExtendedDataRecordEx, operation=Event_DTC_0x000002.GetEventExtendedDataRecordEx
        OpEventGetEventEnableCondition_GetEventEnableCondition_EvtInfo_DTC_0x000002: start-on-event=DemSatellite_0InternalBehavior/GetEventEnableCondition, operation=EvtInfo_DTC_0x000002.GetEventEnableCondition
        OpEventGetDebouncingOfEvent_GetDebouncingOfEvent_EvtInfo_DTC_0x000002: start-on-event=DemSatellite_0InternalBehavior/GetDebouncingOfEvent, operation=EvtInfo_DTC_0x000002.GetDebouncingOfEvent
        OpEventGetMonitorStatus_GetMonitorStatus_EvtInfo_DTC_0x000002: start-on-event=DemSatellite_0InternalBehavior/GetMonitorStatus, operation=EvtInfo_DTC_0x000002.GetMonitorStatus
        OpEventSetEventStatus_SetEventStatus_Event_DTC_0x000002: start-on-event=SetEventStatus, operation=Event_DTC_0x000002.SetEventStatus
        OpEventResetEventStatus_ResetEventStatus_Event_DTC_0x000002: start-on-event=ResetEventStatus, operation=Event_DTC_0x000002.ResetEventStatus
        OpEventResetEventDebounceStatus_ResetEventDebounceStatus_Event_DTC_0x000002: start-on-event=ResetEventDebounceStatus, operation=Event_DTC_0x000002.ResetEventDebounceStatus
      port-api-options:
        {enable-take-address=true, indirect-api=false, port-defined-argument-value{value=1, value-type=Dem_EventIdType}, port=EvtInfo_AutoCreatedDemEvent_NVM_E_INTEGRITY_FAILED}
        {enable-take-address=true, indirect-api=false, port-defined-argument-value{value=2, value-type=Dem_EventIdType}, port=EvtInfo_AutoCreatedDemEvent_NVM_E_LOSS_OF_REDUNDANCY}
        {enable-take-address=true, indirect-api=false, port-defined-argument-value{value=3, value-type=Dem_EventIdType}, port=EvtInfo_AutoCreatedDemEvent_NVM_E_QUEUE_OVERFLOW}
        {enable-take-address=true, indirect-api=false, port-defined-argument-value{value=4, value-type=Dem_EventIdType}, port=EvtInfo_AutoCreatedDemEvent_NVM_E_REQ_FAILED}
        {enable-take-address=true, indirect-api=false, port-defined-argument-value{value=5, value-type=Dem_EventIdType}, port=EvtInfo_AutoCreatedDemEvent_NVM_E_VERIFY_FAILED}
        {enable-take-address=true, indirect-api=false, port-defined-argument-value{value=6, value-type=Dem_EventIdType}, port=EvtInfo_AutoCreatedDemEvent_NVM_E_WRITE_PROTECTED}
        {enable-take-address=true, indirect-api=false, port-defined-argument-value{value=7, value-type=Dem_EventIdType}, port=EvtInfo_AutoCreatedDemEvent_NVM_E_WRONG_BLOCK_ID}
        enable-take-address=true, indirect-api=false, port=DemSatellite_0/GeneralEventInfo
        {enable-take-address=true, indirect-api=false, port-defined-argument-value{value=8, value-type=Dem_EventIdType}, port=EvtInfo_AutoCreatedDemEvent_EcuMConfiguration_ECUM_E_ALL_RUN_REQUESTS_KILLED}
        {enable-take-address=true, indirect-api=false, port-defined-argument-value{value=9, value-type=Dem_EventIdType}, port=EvtInfo_AutoCreatedDemEvent_EcuMConfiguration_ECUM_E_CONFIGURATION_DATA_INCONSISTENT}
        {enable-take-address=true, indirect-api=false, port-defined-argument-value{value=11, value-type=Dem_EventIdType}, port=EvtInfo_AutoCreatedDemEvent_EcuMConfiguration_ECUM_E_RAM_CHECK_FAILED}
        {enable-take-address=true, indirect-api=false, port-defined-argument-value{value=10, value-type=Dem_EventIdType}, port=EvtInfo_AutoCreatedDemEvent_EcuMConfiguration_ECUM_E_IMPROPER_CALLER}
        {enable-take-address=true, indirect-api=false, port-defined-argument-value{value=12, value-type=Dem_EventIdType}, port=EvtInfo_DTC_0x000002}
        {enable-take-address=true, indirect-api=false, port-defined-argument-value{value=12, value-type=Dem_EventIdType}, port=Event_DTC_0x000002}
      15 x runnable:
        Dem_SatelliteMainFunction
        GetEventUdsStatus: can-be-invoked-concurrently=true, symbol=Dem_GetEventUdsStatus
        GetEventStatus: can-be-invoked-concurrently=true, symbol=Dem_GetEventUdsStatus
        GetEventFailed: can-be-invoked-concurrently=true, symbol=Dem_GetEventFailed
        GetEventTested: can-be-invoked-concurrently=true, symbol=Dem_GetEventTested
        GetDTCOfEvent: can-be-invoked-concurrently=true, symbol=Dem_GetDTCOfEvent
        GetFaultDetectionCounter: can-be-invoked-concurrently=true, symbol=Dem_GetFaultDetectionCounter
        GetEventFreezeFrameDataEx: can-be-invoked-concurrently=true, symbol=Dem_GetEventFreezeFrameDataEx
        GetEventExtendedDataRecordEx: can-be-invoked-concurrently=true, symbol=Dem_GetEventExtendedDataRecordEx
        GetEventEnableCondition: can-be-invoked-concurrently=true, symbol=Dem_GetEventEnableCondition
        GetDebouncingOfEvent: can-be-invoked-concurrently=true, symbol=Dem_GetDebouncingOfEvent
        GetMonitorStatus: can-be-invoked-concurrently=true, symbol=Dem_GetMonitorStatus
        SetEventStatus: can-be-invoked-concurrently=true, symbol=Dem_SetEventStatus
        ResetEventStatus: can-be-invoked-concurrently=true, symbol=Dem_ResetEventStatus
        ResetEventDebounceStatus: can-be-invoked-concurrently=true, symbol=Dem_ResetEventDebounceStatus
  swc implementation DemSatellite_0Implementation: programming-language=C, behavior=DemSatellite_0InternalBehavior
